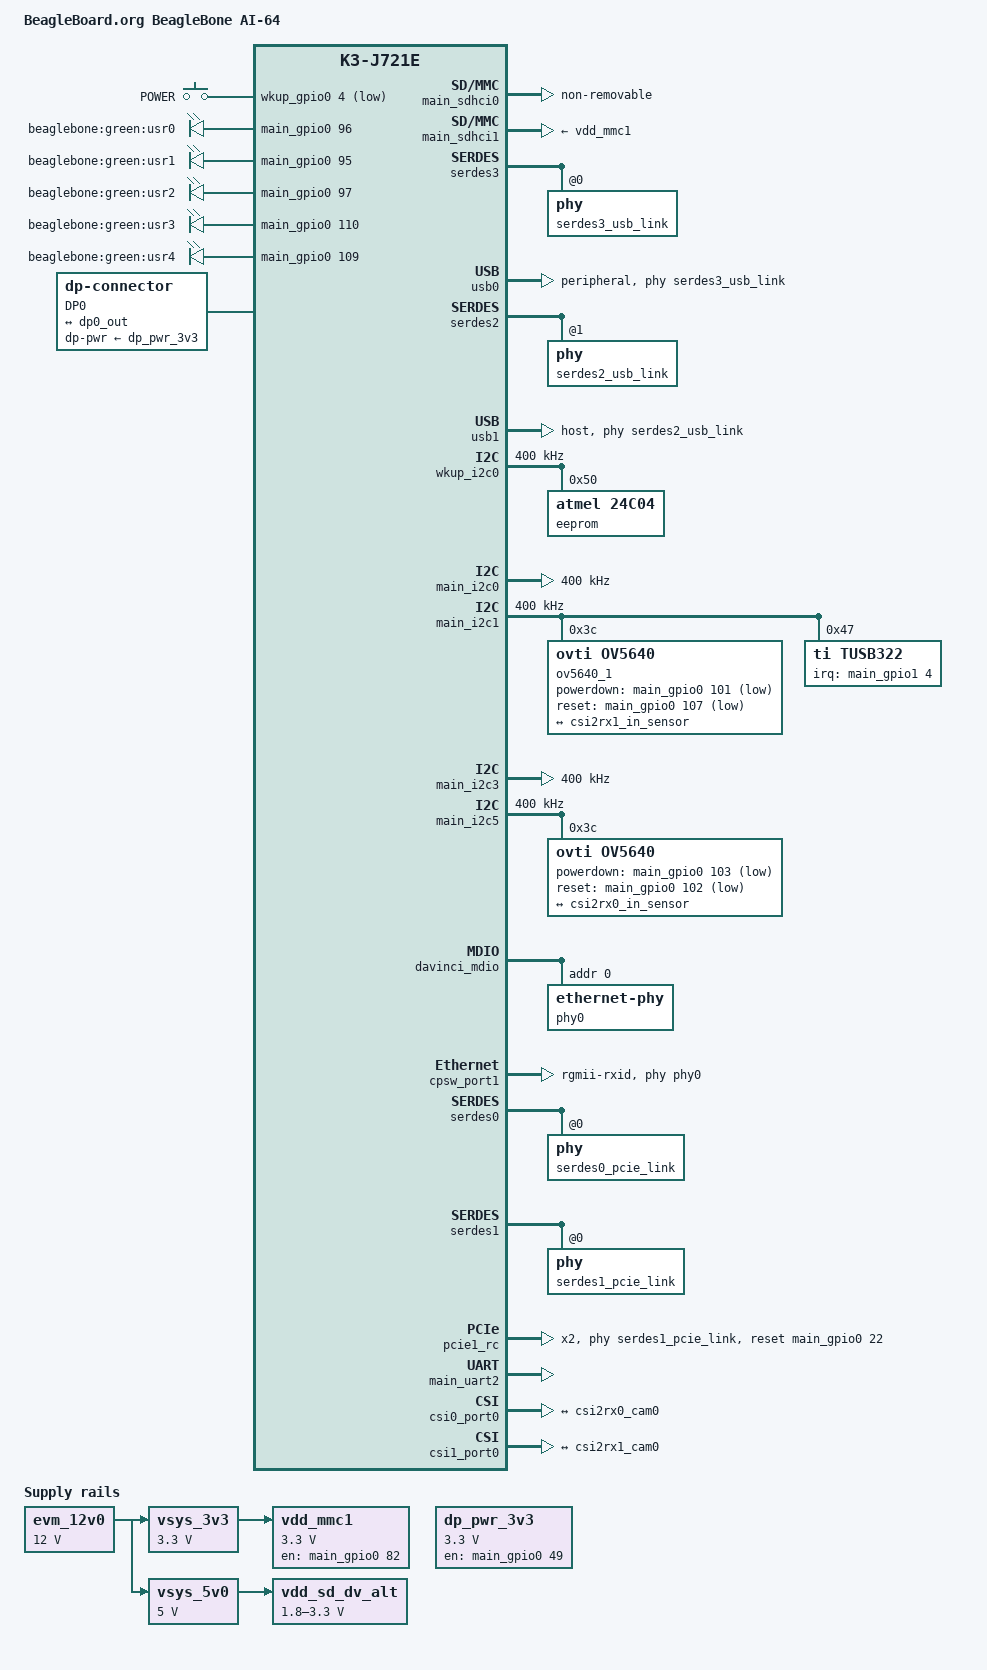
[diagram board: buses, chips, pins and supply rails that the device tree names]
// SPDX-License-Identifier: GPL-2.0
/*
 * Copyright (C) 2022 Texas Instruments Incorporated - https://www.ti.com/
 * Copyright (C) 2022 Jason Kridner, BeagleBoard.org Foundation
 */

/dts-v1/;

#include "k3-j721e-som-p0.dtsi"
//#include "k3-j721e-rtos-memory-map.dtsi"
#include <dt-bindings/gpio/gpio.h>
#include <dt-bindings/input/input.h>
#include <dt-bindings/net/ti-dp83867.h>
#include <dt-bindings/board/k3-j721e-bone-pins.h>

/ {

	model = "BeagleBoard.org BeagleBone AI-64";
	compatible = "beagle,j721e-beagleboneai64", "ti,j721e";

	chosen {
		stdout-path = "serial2:115200n8";
		bootargs = "console=ttyS2,115200n8 earlycon=ns16550a,mmio32,0x02800000";
		base_dtb = "k3-j721e-beagleboneai64.dts";
		base_dtb_timestamp = __TIMESTAMP__;
	};

	gpio_keys: gpio-keys {
		compatible = "gpio-keys";
		autorepeat;
		pinctrl-names = "default";
		pinctrl-0 = <&sw_pwr_pins_default>;

		sw_boot: sw1 {
			status = "disabled";
			label = "BOOT";
			linux,code = <BTN_0>;
			gpios = <&wkup_gpio0 0 GPIO_ACTIVE_LOW>;
		};

		sw_pwr: sw2 {
			label = "POWER";
			linux,code = <KEY_POWER>;
			gpios = <&wkup_gpio0 4 GPIO_ACTIVE_LOW>;
		};
	};

	gpio_leds: gpio-leds {
		compatible = "gpio-leds";
		pinctrl-names = "default";
		pinctrl-0 = <&led_pins_default>;

		usr_led0: usr_led0 {
			label = "beaglebone:green:usr0";
			default-state = "keep";
			linux,default-trigger = "heartbeat";
			gpios = <&main_gpio0 96 GPIO_ACTIVE_HIGH>;
		};

		usr_led1: usr_led1 {
			label = "beaglebone:green:usr1";
			default-state = "keep";
			linux,default-trigger = "mmc0";
			gpios = <&main_gpio0 95 GPIO_ACTIVE_HIGH>;
		};

		usr_led2: usr_led2 {
			label = "beaglebone:green:usr2";
			linux,default-trigger = "cpu";
			gpios = <&main_gpio0 97 GPIO_ACTIVE_HIGH>;
		};

		usr_led3: usr_led3 {
			label = "beaglebone:green:usr3";
			linux,default-trigger = "mmc1";
			gpios = <&main_gpio0 110 GPIO_ACTIVE_HIGH>;
		};

		usr_led4: usr_led4 {
			label = "beaglebone:green:usr4";
			linux,default-trigger = "netdev";
			gpios = <&main_gpio0 109 GPIO_ACTIVE_HIGH>;
		};

		bone_led_P8_03: led_P8_03 {
			status = "disabled";
			linux,default-trigger = "default-off";
			gpios = <gpio_P8_03 GPIO_ACTIVE_HIGH>;
		};

		bone_led_P8_04: led_P8_04 {
			status = "disabled";
			linux,default-trigger = "default-off";
			gpios = <gpio_P8_04 GPIO_ACTIVE_HIGH>;
		};

		bone_led_P8_05: led_P8_05 {
			status = "disabled";
			linux,default-trigger = "default-off";
			gpios = <gpio_P8_05 GPIO_ACTIVE_HIGH>;
		};

		bone_led_P8_06: led_P8_06 {
			status = "disabled";
			linux,default-trigger = "default-off";
			gpios = <gpio_P8_06 GPIO_ACTIVE_HIGH>;
		};

		bone_led_P8_07: led_P8_07 {
			status = "disabled";
			linux,default-trigger = "default-off";
			gpios = <gpio_P8_07 GPIO_ACTIVE_HIGH>;
		};

		bone_led_P8_08: led_P8_08 {
			status = "disabled";
			linux,default-trigger = "default-off";
			gpios = <gpio_P8_08 GPIO_ACTIVE_HIGH>;
		};

		bone_led_P8_09: led_P8_09 {
			status = "disabled";
			linux,default-trigger = "default-off";
			gpios = <gpio_P8_09 GPIO_ACTIVE_HIGH>;
		};

		bone_led_P8_10: led_P8_10 {
			status = "disabled";
			linux,default-trigger = "default-off";
			gpios = <gpio_P8_10 GPIO_ACTIVE_HIGH>;
		};

		bone_led_P8_11: led_P8_11 {
			status = "disabled";
			linux,default-trigger = "default-off";
			gpios = <gpio_P8_11 GPIO_ACTIVE_HIGH>;
		};

		bone_led_P8_12: led_P8_12 {
			status = "disabled";
			linux,default-trigger = "default-off";
			gpios = <gpio_P8_12 GPIO_ACTIVE_HIGH>;
		};

		bone_led_P8_13: led_P8_13 {
			status = "disabled";
			linux,default-trigger = "default-off";
			gpios = <gpio_P8_13 GPIO_ACTIVE_HIGH>;
		};

		bone_led_P8_14: led_P8_14 {
			status = "disabled";
			linux,default-trigger = "default-off";
			gpios = <gpio_P8_14 GPIO_ACTIVE_HIGH>;
		};

		bone_led_P8_15: led_P8_15 {
			status = "disabled";
			linux,default-trigger = "default-off";
			gpios = <gpio_P8_15 GPIO_ACTIVE_HIGH>;
		};

		bone_led_P8_16: led_P8_16 {
			status = "disabled";
			linux,default-trigger = "default-off";
			gpios = <gpio_P8_16 GPIO_ACTIVE_HIGH>;
		};

		bone_led_P8_17: led_P8_17 {
			status = "disabled";
			linux,default-trigger = "default-off";
			gpios = <gpio_P8_17 GPIO_ACTIVE_HIGH>;
		};

		bone_led_P8_18: led_P8_18 {
			status = "disabled";
			linux,default-trigger = "default-off";
			gpios = <gpio_P8_18 GPIO_ACTIVE_HIGH>;
		};

		bone_led_P8_19: led_P8_19 {
			status = "disabled";
			linux,default-trigger = "default-off";
			gpios = <gpio_P8_19 GPIO_ACTIVE_HIGH>;
		};

		bone_led_P8_20: led_P8_20 {
			status = "disabled";
			linux,default-trigger = "default-off";
			gpios = <gpio_P8_20 GPIO_ACTIVE_HIGH>;
		};

		bone_led_P8_21: led_P8_21 {
			status = "disabled";
			linux,default-trigger = "default-off";
			gpios = <gpio_P8_21 GPIO_ACTIVE_HIGH>;
		};

		bone_led_P8_22: led_P8_22 {
			status = "disabled";
			linux,default-trigger = "default-off";
			gpios = <gpio_P8_22 GPIO_ACTIVE_HIGH>;
		};

		bone_led_P8_23: led_P8_23 {
			status = "disabled";
			linux,default-trigger = "default-off";
			gpios = <gpio_P8_23 GPIO_ACTIVE_HIGH>;
		};

		bone_led_P8_24: led_P8_24 {
			status = "disabled";
			linux,default-trigger = "default-off";
			gpios = <gpio_P8_24 GPIO_ACTIVE_HIGH>;
		};

		bone_led_P8_25: led_P8_25 {
			status = "disabled";
			linux,default-trigger = "default-off";
			gpios = <gpio_P8_25 GPIO_ACTIVE_HIGH>;
		};

		bone_led_P8_26: led_P8_26 {
			status = "disabled";
			linux,default-trigger = "default-off";
			gpios = <gpio_P8_26 GPIO_ACTIVE_HIGH>;
		};

		bone_led_P8_27: led_P8_27 {
			status = "disabled";
			linux,default-trigger = "default-off";
			gpios = <gpio_P8_27 GPIO_ACTIVE_HIGH>;
		};

		bone_led_P8_28: led_P8_28 {
			status = "disabled";
			linux,default-trigger = "default-off";
			gpios = <gpio_P8_28 GPIO_ACTIVE_HIGH>;
		};

		bone_led_P8_29: led_P8_29 {
			status = "disabled";
			linux,default-trigger = "default-off";
			gpios = <gpio_P8_29 GPIO_ACTIVE_HIGH>;
		};

		bone_led_P8_30: led_P8_30 {
			status = "disabled";
			linux,default-trigger = "default-off";
			gpios = <gpio_P8_30 GPIO_ACTIVE_HIGH>;
		};

		bone_led_P8_31: led_P8_31 {
			status = "disabled";
			linux,default-trigger = "default-off";
			gpios = <gpio_P8_31 GPIO_ACTIVE_HIGH>;
		};

		bone_led_P8_32: led_P8_32 {
			status = "disabled";
			linux,default-trigger = "default-off";
			gpios = <gpio_P8_32 GPIO_ACTIVE_HIGH>;
		};

		bone_led_P8_33: led_P8_33 {
			status = "disabled";
			linux,default-trigger = "default-off";
			gpios = <gpio_P8_33 GPIO_ACTIVE_HIGH>;
		};

		bone_led_P8_34: led_P8_34 {
			status = "disabled";
			linux,default-trigger = "default-off";
			gpios = <gpio_P8_34 GPIO_ACTIVE_HIGH>;
		};

		bone_led_P8_35: led_P8_35 {
			status = "disabled";
			linux,default-trigger = "default-off";
			gpios = <gpio_P8_35 GPIO_ACTIVE_HIGH>;
		};

		bone_led_P8_36: led_P8_36 {
			status = "disabled";
			linux,default-trigger = "default-off";
			gpios = <gpio_P8_36 GPIO_ACTIVE_HIGH>;
		};

		bone_led_P8_37: led_P8_37 {
			status = "disabled";
			linux,default-trigger = "default-off";
			gpios = <gpio_P8_37 GPIO_ACTIVE_HIGH>;
		};

		bone_led_P8_38: led_P8_38 {
			status = "disabled";
			linux,default-trigger = "default-off";
			gpios = <gpio_P8_38 GPIO_ACTIVE_HIGH>;
		};

		bone_led_P8_39: led_P8_39 {
			status = "disabled";
			linux,default-trigger = "default-off";
			gpios = <gpio_P8_39 GPIO_ACTIVE_HIGH>;
		};

		bone_led_P8_40: led_P8_40 {
			status = "disabled";
			linux,default-trigger = "default-off";
			gpios = <gpio_P8_40 GPIO_ACTIVE_HIGH>;
		};

		bone_led_P8_41: led_P8_41 {
			status = "disabled";
			linux,default-trigger = "default-off";
			gpios = <gpio_P8_41 GPIO_ACTIVE_HIGH>;
		};

		bone_led_P8_42: led_P8_42 {
			status = "disabled";
			linux,default-trigger = "default-off";
			gpios = <gpio_P8_42 GPIO_ACTIVE_HIGH>;
		};

		bone_led_P8_43: led_P8_43 {
			status = "disabled";
			linux,default-trigger = "default-off";
			gpios = <gpio_P8_43 GPIO_ACTIVE_HIGH>;
		};

		bone_led_P8_44: led_P8_44 {
			status = "disabled";
			linux,default-trigger = "default-off";
			gpios = <gpio_P8_44 GPIO_ACTIVE_HIGH>;
		};

		bone_led_P8_45: led_P8_45 {
			status = "disabled";
			linux,default-trigger = "default-off";
			gpios = <gpio_P8_45 GPIO_ACTIVE_HIGH>;
		};

		bone_led_P8_46: led_P8_46 {
			status = "disabled";
			linux,default-trigger = "default-off";
			gpios = <gpio_P8_46 GPIO_ACTIVE_HIGH>;
		};

		bone_led_P9_11: led_P9_11 {
			status = "disabled";
			linux,default-trigger = "default-off";
			gpios = <gpio_P9_11 GPIO_ACTIVE_HIGH>;
		};

		bone_led_P9_12: led_P9_12 {
			status = "disabled";
			linux,default-trigger = "default-off";
			gpios = <gpio_P9_12 GPIO_ACTIVE_HIGH>;
		};

		bone_led_P9_13: led_P9_13 {
			status = "disabled";
			linux,default-trigger = "default-off";
			gpios = <gpio_P9_13 GPIO_ACTIVE_HIGH>;
		};

		bone_led_P9_14: led_P9_14 {
			status = "disabled";
			linux,default-trigger = "default-off";
			gpios = <gpio_P9_14 GPIO_ACTIVE_HIGH>;
		};

		bone_led_P9_15: led_P9_15 {
			status = "disabled";
			linux,default-trigger = "default-off";
			gpios = <gpio_P9_15 GPIO_ACTIVE_HIGH>;
		};

		bone_led_P9_16: led_P9_16 {
			status = "disabled";
			linux,default-trigger = "default-off";
			gpios = <gpio_P9_16 GPIO_ACTIVE_HIGH>;
		};

		bone_led_P9_17: led_P9_17 {
			status = "disabled";
			linux,default-trigger = "default-off";
			gpios = <gpio_P9_17 GPIO_ACTIVE_HIGH>;
		};

		bone_led_P9_18: led_P9_18 {
			status = "disabled";
			linux,default-trigger = "default-off";
			gpios = <gpio_P9_18 GPIO_ACTIVE_HIGH>;
		};

		bone_led_P9_19: led_P9_19 {
			status = "disabled";
			linux,default-trigger = "default-off";
			gpios = <gpio_P9_19 GPIO_ACTIVE_HIGH>;
		};

		bone_led_P9_20: led_P9_20 {
			status = "disabled";
			linux,default-trigger = "default-off";
			gpios = <gpio_P9_20 GPIO_ACTIVE_HIGH>;
		};

		bone_led_P9_21: led_P9_21 {
			status = "disabled";
			linux,default-trigger = "default-off";
			gpios = <gpio_P9_21 GPIO_ACTIVE_HIGH>;
		};

		bone_led_P9_22: led_P9_22 {
			status = "disabled";
			linux,default-trigger = "default-off";
			gpios = <gpio_P9_22 GPIO_ACTIVE_HIGH>;
		};

		bone_led_P9_23: led_P9_23 {
			status = "disabled";
			linux,default-trigger = "default-off";
			gpios = <gpio_P9_23 GPIO_ACTIVE_HIGH>;
		};

		bone_led_P9_24: led_P9_24 {
			status = "disabled";
			linux,default-trigger = "default-off";
			gpios = <gpio_P9_24 GPIO_ACTIVE_HIGH>;
		};

		bone_led_P9_25: led_P9_25 {
			status = "disabled";
			linux,default-trigger = "default-off";
			gpios = <gpio_P9_25 GPIO_ACTIVE_HIGH>;
		};

		bone_led_P9_26: led_P9_26 {
			status = "disabled";
			linux,default-trigger = "default-off";
			gpios = <gpio_P9_26 GPIO_ACTIVE_HIGH>;
		};

		bone_led_P9_27: led_P9_27 {
			status = "disabled";
			linux,default-trigger = "default-off";
			gpios = <gpio_P9_27 GPIO_ACTIVE_HIGH>;
		};

		bone_led_P9_28: led_P9_28 {
			status = "disabled";
			linux,default-trigger = "default-off";
			gpios = <gpio_P9_28 GPIO_ACTIVE_HIGH>;
		};

		bone_led_P9_29: led_P9_29 {
			status = "disabled";
			linux,default-trigger = "default-off";
			gpios = <gpio_P9_29 GPIO_ACTIVE_HIGH>;
		};

		bone_led_P9_30: led_P9_30 {
			status = "disabled";
			linux,default-trigger = "default-off";
			gpios = <gpio_P9_30 GPIO_ACTIVE_HIGH>;
		};

		bone_led_P9_31: led_P9_31 {
			status = "disabled";
			linux,default-trigger = "default-off";
			gpios = <gpio_P9_31 GPIO_ACTIVE_HIGH>;
		};

		bone_led_P9_33: led_P9_33 {
			status = "disabled";
			linux,default-trigger = "default-off";
			gpios = <gpio_P9_33 GPIO_ACTIVE_HIGH>;
		};

		bone_led_P9_35: led_P9_35 {
			status = "disabled";
			linux,default-trigger = "default-off";
			gpios = <gpio_P9_35 GPIO_ACTIVE_HIGH>;
		};

		bone_led_P9_36: led_P9_36 {
			status = "disabled";
			linux,default-trigger = "default-off";
			gpios = <gpio_P9_36 GPIO_ACTIVE_HIGH>;
		};

		bone_led_P9_37: led_P9_37 {
			status = "disabled";
			linux,default-trigger = "default-off";
			gpios = <gpio_P9_37 GPIO_ACTIVE_HIGH>;
		};

		bone_led_P9_38: led_P9_38 {
			status = "disabled";
			linux,default-trigger = "default-off";
			gpios = <gpio_P9_38 GPIO_ACTIVE_HIGH>;
		};

		bone_led_P9_39: led_P9_39 {
			status = "disabled";
			linux,default-trigger = "default-off";
			gpios = <gpio_P9_39 GPIO_ACTIVE_HIGH>;
		};

		bone_led_P9_40: led_P9_40 {
			status = "disabled";
			linux,default-trigger = "default-off";
			gpios = <gpio_P9_40 GPIO_ACTIVE_HIGH>;
		};

		bone_led_P9_41: led_P9_41 {
			status = "disabled";
			linux,default-trigger = "default-off";
			gpios = <gpio_P9_41 GPIO_ACTIVE_HIGH>;
		};

		bone_led_P9_42: led_P9_42 {
			status = "disabled";
			linux,default-trigger = "default-off";
			gpios = <gpio_P8_42 GPIO_ACTIVE_HIGH>;
		};
	};

	/* Dummy driver to request setup for cape header pins */
	cape_header: pinmux_dummy {
		compatible = "gpio-leds";
		pinctrl-names = "default";
		pinctrl-0 = <
			&P8_03_default_pin
			&P8_04_default_pin
			&P8_05_default_pin
			&P8_06_default_pin
			&P8_07_default_pin
			&P8_08_default_pin
			&P8_09_default_pin
			&P8_10_default_pin
			&P8_11_default_pin
			&P8_12_default_pin
			&P8_13_default_pin
			&P8_14_default_pin
			&P8_15_default_pin
			&P8_16_default_pin
			&P8_17_default_pin
			&P8_18_default_pin
			&P8_19_default_pin
			&P8_20_default_pin
			&P8_21_default_pin
			&P8_22_default_pin
			&P8_23_default_pin
			&P8_24_default_pin
			&P8_25_default_pin
			&P8_26_default_pin
			&P8_27_default_pin
			&P8_28_default_pin
			&P8_29_default_pin
			&P8_30_default_pin
			&P8_31_default_pin
			&P8_32_default_pin
			&P8_33_default_pin
			&P8_34_default_pin
			&P8_35_default_pin
			&P8_36_default_pin
			&P8_37_default_pin
			&P8_38_default_pin
			&P8_39_default_pin
			&P8_40_default_pin
			&P8_41_default_pin
			&P8_42_default_pin
			&P8_43_default_pin
			&P8_44_default_pin
			&P8_45_default_pin
			&P8_46_default_pin
			&P9_11_default_pin
			&P9_12_default_pin
			&P9_13_default_pin
			&P9_14_default_pin
			&P9_15_default_pin
			&P9_16_default_pin
			&P9_17_default_pin
			&P9_18_default_pin
			&P9_19_default_pin
			&P9_20_default_pin
			&P9_21_default_pin
			&P9_22_default_pin
			&P9_23_default_pin
			&P9_24_default_pin
			&P9_25_default_pin
			&P9_26_default_pin
			&P9_27_default_pin
			&P9_28_default_pin
			&P9_29_default_pin
			&P9_30_default_pin
			&P9_31_default_pin
			&P9_33_default_pin
			&P9_35_default_pin
			&P9_36_default_pin
			&P9_37_default_pin
			&P9_38_default_pin
			&P9_39_default_pin
			&P9_40_default_pin
			&P9_41_default_pin
			&P9_42_default_pin
		>;
	};

	evm_12v0: fixedregulator-evm12v0 {
		/* main supply */
		compatible = "regulator-fixed";
		regulator-name = "evm_12v0";
		regulator-min-microvolt = <12000000>;
		regulator-max-microvolt = <12000000>;
		regulator-always-on;
		regulator-boot-on;
	};

	vsys_3v3: fixedregulator-vsys3v3 {
		/* Output of LMS140 */
		compatible = "regulator-fixed";
		regulator-name = "vsys_3v3";
		regulator-min-microvolt = <3300000>;
		regulator-max-microvolt = <3300000>;
		vin-supply = <&evm_12v0>;
		regulator-always-on;
		regulator-boot-on;
	};

	vsys_5v0: fixedregulator-vsys5v0 {
		/* Output of LM5140 */
		compatible = "regulator-fixed";
		regulator-name = "vsys_5v0";
		regulator-min-microvolt = <5000000>;
		regulator-max-microvolt = <5000000>;
		vin-supply = <&evm_12v0>;
		regulator-always-on;
		regulator-boot-on;
	};

	vdd_mmc1: fixedregulator-sd {
		compatible = "regulator-fixed";
		pinctrl-names = "default";
		pinctrl-0 = <&sd_pwr_en_pins_default>;
		regulator-name = "vdd_mmc1";
		regulator-min-microvolt = <3300000>;
		regulator-max-microvolt = <3300000>;
		regulator-boot-on;
		enable-active-high;
		vin-supply = <&vsys_3v3>;
		gpios = <&main_gpio0 82 GPIO_ACTIVE_HIGH>;
	};

	vdd_sd_dv_alt: gpio-regulator-TLV71033 {
		compatible = "regulator-gpio";
		pinctrl-names = "default";
		pinctrl-0 = <&vdd_sd_dv_alt_pins_default>;
		regulator-name = "tlv71033";
		regulator-min-microvolt = <1800000>;
		regulator-max-microvolt = <3300000>;
		regulator-boot-on;
		vin-supply = <&vsys_5v0>;
		gpios = <&main_gpio0 117 GPIO_ACTIVE_HIGH>;
		states = <1800000 0x0>,
			 <3300000 0x1>;
	};

	cpsw9g_virt_mac: main_r5fss_cpsw9g_virt_mac0 {
		compatible = "ti,j721e-cpsw-virt-mac";
		dma-coherent;
		ti,psil-base = <0x4a00>;
		ti,remote-name = "mpu_1_0_ethswitch-device-0";

		dmas = <&main_udmap 0xca00>,
		       <&main_udmap 0xca01>,
		       <&main_udmap 0xca02>,
		       <&main_udmap 0xca03>,
		       <&main_udmap 0xca04>,
		       <&main_udmap 0xca05>,
		       <&main_udmap 0xca06>,
		       <&main_udmap 0xca07>,
		       <&main_udmap 0x4a00>;
		dma-names = "tx0", "tx1", "tx2", "tx3",
			    "tx4", "tx5", "tx6", "tx7",
			    "rx";

		virt_emac_port {
			ti,label = "virt-port";
			/* local-mac-address = [0 0 0 0 0 0]; */
		};
	};

	transceiver1: can-phy@0 {
		status = "disabled";
	};

	transceiver2: can-phy@1 {
		status = "disabled";
	};

	dp_pwr_3v3: fixedregulator-dp-prw {
		compatible = "regulator-fixed";
		pinctrl-names = "default";
		pinctrl-0 = <&dp0_3v3_en_pins_default>;
		regulator-name = "dp-pwr";
		regulator-min-microvolt = <3300000>;
		regulator-max-microvolt = <3300000>;
		gpios = <&main_gpio0 49 GPIO_ACTIVE_HIGH>; /* DP0_PWR_SW_EN */
		enable-active-high;

		/* Always on for now, until dp-connector driver can handle this */
		regulator-always-on;
	};

	dp0: connector {
		compatible = "dp-connector";
		label = "DP0";
		type = "full-size";
		dp-pwr-supply = <&dp_pwr_3v3>;

		port {
			dp_connector_in: endpoint {
				remote-endpoint = <&dp0_out>;
			};
		};
	};

	clk_ov5640_fixed: ov5640-xclk {
		compatible = "fixed-clock";
		#clock-cells = <0>;
		clock-frequency = <25000000>;
	};
};

&main_pmx0 {
	led_pins_default: led-pins-default {
		pinctrl-single,pins = <
			J721E_IOPAD(0x184, PIN_INPUT, 7) /* (T23) RGMII5_RD0.GPIO0_96 */
			J721E_IOPAD(0x180, PIN_INPUT, 7) /* (R23) RGMII5_RD1.GPIO0_95 */
			J721E_IOPAD(0x188, PIN_INPUT, 7) /* (Y28) RGMII6_TX_CTL.GPIO0_97 */
			J721E_IOPAD(0x1bc, PIN_INPUT, 7) /* (V24) MDIO0_MDC.GPIO0_110 */
			J721E_IOPAD(0x1b8, PIN_INPUT, 7) /* (V26) MDIO0_MDIO.GPIO0_109 */
		>;
	};

	main_mmc1_pins_default: main-mmc1-pins-default {
		pinctrl-single,pins = <
			J721E_IOPAD(0x254, PIN_INPUT, 0) /* (R29) MMC1_CMD */
			J721E_IOPAD(0x250, PIN_INPUT, 0) /* (P25) MMC1_CLK */
			J721E_IOPAD(0x2ac, PIN_INPUT, 0) /* (P25) MMC1_CLKLB */
			J721E_IOPAD(0x24c, PIN_INPUT, 0) /* (R24) MMC1_DAT0 */
			J721E_IOPAD(0x248, PIN_INPUT, 0) /* (P24) MMC1_DAT1 */
			J721E_IOPAD(0x244, PIN_INPUT, 0) /* (R25) MMC1_DAT2 */
			J721E_IOPAD(0x240, PIN_INPUT, 0) /* (R26) MMC1_DAT3 */
			J721E_IOPAD(0x258, PIN_INPUT, 0) /* (P23) MMC1_SDCD */
		>;
	};

	sd_pwr_en_pins_default: sd-pwr-en-pins-default {
		pinctrl-single,pins = <
			J721E_IOPAD(0x14c, PIN_INPUT, 7) /* (AA29) PRG0_PRU1_GPO19.GPIO0_82 */
		>;
	};

	vdd_sd_dv_alt_pins_default: vdd-sd-dv-alt-pins-default {
		pinctrl-single,pins = <
			J721E_IOPAD(0x1d8, PIN_INPUT, 7) /* (W4) SPI1_CS1.GPIO0_117 */
		>;
	};

	main_usbss0_pins_default: main-usbss0-pins-default {
		pinctrl-single,pins = <
			J721E_IOPAD(0x210, PIN_INPUT, 7) /* (W3) MCAN1_RX.GPIO1_3 - USBC_DIR */
		>;
	};

	tusb322_pins_default: tusb322-pins-default {
		pinctrl-single,pins = <
			J721E_IOPAD(0x214, PIN_INPUT, 7) /* (V4) MCAN1_TX.GPIO1_4 -- USBC_INT */
		>;
	};

	main_usbss1_pins_default: main-usbss1-pins-default {
		pinctrl-single,pins = <
			J721E_IOPAD(0x290, INPUT_DISABLE, 1) /* (U6) USB0_DRVVBUS.USB1_DRVVBUS */
		>;
	};

	dp0_3v3_en_pins_default:dp0-3v3-en-pins-default {
		pinctrl-single,pins = <
			J721E_IOPAD(0xc8, PIN_INPUT, 7) /* (AE26) PRG0_PRU0_GPO6.GPIO0_49 */
		>;
	};

	dp0_pins_default: dp0-pins-default {
		pinctrl-single,pins = <
			J721E_IOPAD(0x1c4, PIN_INPUT, 5) /* (Y4) SPI0_CS1.DP0_HPD */
		>;
	};

	main_i2c0_pins_default: main-i2c0-pins-default {
		pinctrl-single,pins = <
			J721E_IOPAD(0x220, PIN_INPUT_PULLUP, 0) /* (AC5) I2C0_SCL */
			J721E_IOPAD(0x224, PIN_INPUT_PULLUP, 0) /* (AA5) I2C0_SDA */
		>;
	};

	main_i2c1_pins_default: main-i2c1-pins-default {
		pinctrl-single,pins = <
			J721E_IOPAD(0x228, PIN_INPUT_PULLUP, 0) /* (Y6) I2C1_SCL */
			J721E_IOPAD(0x22c, PIN_INPUT_PULLUP, 0) /* (AA6) I2C1_SDA */
		>;
	};

	main_i2c3_pins_default: main-i2c3-pins-default {
		pinctrl-single,pins = <
			J721E_IOPAD(0x270, PIN_INPUT_PULLUP, 4) /* (T26) MMC2_CLK.I2C3_SCL */
			J721E_IOPAD(0x274, PIN_INPUT_PULLUP, 4) /* (T25) MMC2_CMD.I2C3_SDA */
		>;
	};

	main_i2c5_pins_default: main-i2c5-pins-default {
		pinctrl-single,pins = <
			J721E_IOPAD(0x150, PIN_INPUT_PULLUP, 2) /* (Y26) PRG0_MDIO0_MDIO.I2C5_SCL */
			J721E_IOPAD(0x154, PIN_INPUT_PULLUP, 2) /* (AA27) PRG0_MDIO0_MDC.I2C5_SDA */
		>;
	};

	main_spi6_pins_default: main-spi6-pins-default {
		pinctrl-single,pins = <
			J721E_IOPAD(0x74, INPUT_DISABLE, 4) /* (AC21) PRG1_PRU1_GPO7.SPI6_CS0 */
			J721E_IOPAD(0x28, INPUT_DISABLE, 4) /* (AG20) PRG1_PRU0_GPO9.SPI6_CS1 */
			J721E_IOPAD(0x9c, INPUT_DISABLE, 4) /* (AC22) PRG1_PRU1_GPO17.SPI6_CLK */
			J721E_IOPAD(0xa0, INPUT_DISABLE, 4) /* (AJ22) PRG1_PRU1_GPO18.SPI6_D0 */
			J721E_IOPAD(0xa4, PIN_INPUT, 4) /* (AH22) PRG1_PRU1_GPO19.SPI6_D1 */
		>;
	};

	csi0_gpio_pins_default: csi0-gpio-pins-default {
		pinctrl-single,pins = <
			J721E_IOPAD(0x19c, PIN_INPUT_PULLDOWN, 7) /* (W27) RGMII6_TD0.GPIO0_102 */
			J721E_IOPAD(0x1a0, PIN_INPUT_PULLDOWN, 7) /* (W29) RGMII6_TXC.GPIO0_103 */
		>;
	};

	csi1_gpio_pins_default: csi1-gpio-pins-default {
		pinctrl-single,pins = <
			J721E_IOPAD(0x198, PIN_INPUT_PULLDOWN, 7) /* (V25) RGMII6_TD1.GPIO0_101 */
			J721E_IOPAD(0x1b0, PIN_INPUT_PULLDOWN, 7) /* (W24) RGMII6_RD1.GPIO0_107 */
		>;
	};

/* macro: BONE_PIN( <pin>, <mode_name>, <register_value_macro(s)> */
#define BONE_PIN(XX,ZZ,QQ) \
	XX##_##ZZ##_pin: pinmux_##XX##_##ZZ##_pin { pinctrl-single,pins = < QQ >; };

	/* I2C : https://elinux.org/Beagleboard:BeagleBone_cape_interface_spec#I2C */
	/* i2c6 P9.17 P9.18 */
	/* i2c2 P9.19 P9.20 */
	/* i2c4 P9.24 P9.26 */

	/* CAN : https://elinux.org/Beagleboard:BeagleBone_cape_interface_spec#CAN */
	/* mcan0 P9.20 P9.19 */
	/* mcan4 P9.26 P9.24 */
	/* mcan5 P8.08 P8.07 */

	/* SPI : https://elinux.org/Beagleboard:BeagleBone_cape_interface_spec#SPI */
	/* spi6 P9.18 P9.21 P9.22 P9.16 P9.23 */
	/* spi7 P9.30 P9.29 P9.31 P9.29 P9.42 */

	/* UART : https://elinux.org/Beagleboard:BeagleBone_cape_interface_spec#UART */
	/* uart0 P9.13 P9.11 */
	/* uart2 P9.24 P9.22 */
	/* uart5 P8.37 P8.38 P8.32 P8.31 */

	/* PWM: https://elinux.org/Beagleboard:BeagleBone_cape_interface_spec#PWM */
	/* ehrpwm1 P9.22 P9.21 */
	/* ehrpwm2 P9.14 P9.16 */
	/* ehrpwm0 P8.19 P8.13 */

	/* Full P8/P9 header mode definitions */
	/* P8_01 - GND */
	/* P8_02 - GND */

	/* P8_03 (AH21) PRG1_PRU0_GPO19 (gpio0_20) AH21_MCAN6_TX */
	BONE_PIN(P8_03, default,   P8_03(PIN_INPUT, 7))
	BONE_PIN(P8_03, pruout,    P8_03(PIN_OUTPUT, 0))	/* prg1_pru0_gpo19 */
	BONE_PIN(P8_03, pruin,     P8_03(PIN_INPUT, 1))		/* prg1_pru0_gpi19 */
	BONE_PIN(P8_03, gpio,      P8_03(PIN_INPUT, 7))
	BONE_PIN(P8_03, gpio_pu,   P8_03(PIN_INPUT_PULLUP, 7))
	BONE_PIN(P8_03, gpio_pd,   P8_03(PIN_INPUT_PULLDOWN, 7))

	/* P8_04 (AC29) PRG0_PRU0_GPO5 (gpio0_48) AC29_SYS_BOOTMODE2 */
	BONE_PIN(P8_04, default,   P8_04(PIN_INPUT, 7))
	BONE_PIN(P8_04, pruout,    P8_04(PIN_OUTPUT, 0))	/* prg0_pru0_gpo5 */
	BONE_PIN(P8_04, pruin,     P8_04(PIN_INPUT, 1))		/* prg0_pru0_gpi5 */
	BONE_PIN(P8_04, gpio,      P8_04(PIN_INPUT, 7))
	BONE_PIN(P8_04, gpio_pu,   P8_04(PIN_INPUT_PULLUP, 7))
	BONE_PIN(P8_04, gpio_pd,   P8_04(PIN_INPUT_PULLDOWN, 7))

	/* P8_05 (AH25) PRG1_PRU1_GPO12 (gpio0_33) AH25_MCAN7_TX */
	BONE_PIN(P8_05, default,   P8_05(PIN_INPUT, 7))
	BONE_PIN(P8_05, pruout,    P8_05(PIN_OUTPUT, 0))	/* prg1_pru1_gpo12 */
	BONE_PIN(P8_05, pruin,     P8_05(PIN_INPUT, 1))		/* prg1_pru1_gpi12 */
	BONE_PIN(P8_05, gpio,      P8_05(PIN_INPUT, 7))
	BONE_PIN(P8_05, gpio_pu,   P8_05(PIN_INPUT_PULLUP, 7))
	BONE_PIN(P8_05, gpio_pd,   P8_05(PIN_INPUT_PULLDOWN, 7))

	/* P8_06 (AG25) PRG1_PRU1_GPO13 (gpio0_34) AG25_MCAN7_RX */
	BONE_PIN(P8_06, default,   P8_06(PIN_INPUT, 7))
	BONE_PIN(P8_06, pruout,    P8_06(PIN_OUTPUT, 0))	/* prg1_pru1_gpo13 */
	BONE_PIN(P8_06, pruin,     P8_06(PIN_INPUT, 1))		/* prg1_pru1_gpi13 */
	BONE_PIN(P8_06, gpio,      P8_06(PIN_INPUT, 7))
	BONE_PIN(P8_06, gpio_pu,   P8_06(PIN_INPUT_PULLUP, 7))
	BONE_PIN(P8_06, gpio_pd,   P8_06(PIN_INPUT_PULLDOWN, 7))

	/* P8_07 (AD24) PRG1_PRU0_GPO14 (gpio0_15) AD24_MCAN5_RX */
	BONE_PIN(P8_07, default,   P8_07(PIN_INPUT, 7))
	BONE_PIN(P8_07, pruout,    P8_07(PIN_OUTPUT, 0))	/* prg1_pru0_gpo14 */
	BONE_PIN(P8_07, pruin,     P8_07(PIN_INPUT, 1))		/* prg1_pru0_gpi14 */
	BONE_PIN(P8_07, can,       P8_07(PIN_INPUT, 6))	/* mcan5_rx */
	BONE_PIN(P8_07, gpio,      P8_07(PIN_INPUT, 7))
	BONE_PIN(P8_07, gpio_pu,   P8_07(PIN_INPUT_PULLUP, 7))
	BONE_PIN(P8_07, gpio_pd,   P8_07(PIN_INPUT_PULLDOWN, 7))

	/* P8_08 (AG24) PRG1_PRU0_GPO13 (gpio0_14) AG24_MCAN5_TX */
	BONE_PIN(P8_08, default,   P8_08(PIN_INPUT, 7))
	BONE_PIN(P8_08, pruout,    P8_08(PIN_OUTPUT, 0))	/* prg1_pru0_gpo13 */
	BONE_PIN(P8_08, pruin,     P8_08(PIN_INPUT, 1))		/* prg1_pru0_gpi13 */
	BONE_PIN(P8_08, can,       P8_08(PIN_OUTPUT, 6))	/* mcan5_tx */
	BONE_PIN(P8_08, gpio,      P8_08(PIN_INPUT, 7))
	BONE_PIN(P8_08, gpio_pu,   P8_08(PIN_INPUT_PULLUP, 7))
	BONE_PIN(P8_08, gpio_pd,   P8_08(PIN_INPUT_PULLDOWN, 7))

	/* P8_09 (AE24) PRG1_PRU0_GPO16 (gpio0_17) AE24_MCAN6_RX */
	BONE_PIN(P8_09, default,   P8_09(PIN_INPUT, 7))
	BONE_PIN(P8_09, pruout,    P8_09(PIN_OUTPUT, 0))	/* prg1_pru0_gpo16 */
	BONE_PIN(P8_09, pruin,     P8_09(PIN_INPUT, 1))		/* prg1_pru0_gpi16 */
	BONE_PIN(P8_09, gpio,      P8_09(PIN_INPUT, 7))
	BONE_PIN(P8_09, gpio_pu,   P8_09(PIN_INPUT_PULLUP, 7))
	BONE_PIN(P8_09, gpio_pd,   P8_09(PIN_INPUT_PULLDOWN, 7))

	/* P8_10 (AC24) PRG1_PRU0_GPO15 (gpio0_16) AC24_MCAN6_TX */
	BONE_PIN(P8_10, default,   P8_10(PIN_INPUT, 7))
	BONE_PIN(P8_10, pruout,    P8_10(PIN_OUTPUT, 0))	/* prg1_pru0_gpo15 */
	BONE_PIN(P8_10, pruin,     P8_10(PIN_INPUT, 1))		/* prg1_pru0_gpi15 */
	BONE_PIN(P8_10, gpio,      P8_10(PIN_INPUT, 7))
	BONE_PIN(P8_10, gpio_pu,   P8_10(PIN_INPUT_PULLUP, 7))
	BONE_PIN(P8_10, gpio_pd,   P8_10(PIN_INPUT_PULLDOWN, 7))

	/* P8_11 (AB24) PRG0_PRU0_GPO17 (gpio0_60) AB24_SYS_BOOTMODE7 */
	BONE_PIN(P8_11, default,   P8_11(PIN_INPUT, 7))
	BONE_PIN(P8_11, pruout,    P8_11(PIN_OUTPUT, 0))	/* prg0_pru0_gpo17 */
	BONE_PIN(P8_11, pruin,     P8_11(PIN_INPUT, 1))		/* prg0_pru0_gpi17 */
	BONE_PIN(P8_11, gpio,      P8_11(PIN_INPUT, 7))
	BONE_PIN(P8_11, gpio_pu,   P8_11(PIN_INPUT_PULLUP, 7))
	BONE_PIN(P8_11, gpio_pd,   P8_11(PIN_INPUT_PULLDOWN, 7))

	/* P8_12 (AH28) PRG0_PRU0_GPO16 (gpio0_59) AH28_PRG0_PWM0_A2 */
	BONE_PIN(P8_12, default,   P8_12(PIN_INPUT, 7))
	BONE_PIN(P8_12, pruout,    P8_12(PIN_OUTPUT, 0))	/* prg0_pru0_gpo16 */
	BONE_PIN(P8_12, pruin,     P8_12(PIN_INPUT, 1))		/* prg0_pru0_gpi16 */
	BONE_PIN(P8_12, gpio,      P8_12(PIN_INPUT, 7))
	BONE_PIN(P8_12, gpio_pu,   P8_12(PIN_INPUT_PULLUP, 7))
	BONE_PIN(P8_12, gpio_pd,   P8_12(PIN_INPUT_PULLDOWN, 7))

	/* P8_13 (V27) RGMII5_TD1 (gpio0_89) V27_EHRPWM0_B */
	BONE_PIN(P8_13, default,   P8_13(PIN_INPUT, 7))
	BONE_PIN(P8_13, gpio,      P8_13(PIN_INPUT, 7))
	BONE_PIN(P8_13, gpio_pu,   P8_13(PIN_INPUT_PULLUP, 7))
	BONE_PIN(P8_13, gpio_pd,   P8_13(PIN_INPUT_PULLDOWN, 7))
	BONE_PIN(P8_13, pwm,       P8_13(PIN_OUTPUT, 6))	/* ehrpwm0_b */

	/* P8_14 (AF27) PRG0_PRU1_GPO12 (gpio0_75) AF27_PRG0_PWM1_A0 */
	BONE_PIN(P8_14, default,   P8_14(PIN_INPUT, 7))
	BONE_PIN(P8_14, pruout,    P8_14(PIN_OUTPUT, 0))	/* prg0_pru1_gpo12 */
	BONE_PIN(P8_14, pruin,     P8_14(PIN_INPUT, 1))		/* prg0_pru1_gpi12 */
	BONE_PIN(P8_14, gpio,      P8_14(PIN_INPUT, 7))
	BONE_PIN(P8_14, gpio_pu,   P8_14(PIN_INPUT_PULLUP, 7))
	BONE_PIN(P8_14, gpio_pd,   P8_14(PIN_INPUT_PULLDOWN, 7))

	/* P8_15 (AB29) PRG0_PRU0_GPO18 (gpio0_61) AB29_PRG0_ECAP0_IN_APWM_OUT */
	BONE_PIN(P8_15, default,   P8_15(PIN_INPUT, 7))
	BONE_PIN(P8_15, pruout,    P8_15(PIN_OUTPUT, 0))	/* prg0_pru0_gpo18 */
	BONE_PIN(P8_15, pruin,     P8_15(PIN_INPUT, 1))		/* prg0_pru0_gpi18 */
	BONE_PIN(P8_15, gpio,      P8_15(PIN_INPUT, 7))
	BONE_PIN(P8_15, gpio_pu,   P8_15(PIN_INPUT_PULLUP, 7))
	BONE_PIN(P8_15, gpio_pd,   P8_15(PIN_INPUT_PULLDOWN, 7))

	/* P8_16 (AB28) PRG0_PRU0_GPO19 (gpio0_62) AB28_PRG0_PWM0_TZ_OUT */
	BONE_PIN(P8_16, default,   P8_16(PIN_INPUT, 7))
	BONE_PIN(P8_16, pruout,    P8_16(PIN_OUTPUT, 0))	/* prg0_pru0_gpo19 */
	BONE_PIN(P8_16, pruin,     P8_16(PIN_INPUT, 1))		/* prg0_pru0_gpi19 */
	BONE_PIN(P8_16, gpio,      P8_16(PIN_INPUT, 7))
	BONE_PIN(P8_16, gpio_pu,   P8_16(PIN_INPUT_PULLUP, 7))
	BONE_PIN(P8_16, gpio_pd,   P8_16(PIN_INPUT_PULLDOWN, 7))

	/* P8_17 (AF22) PRG1_PRU0_GPO2 (gpio0_3) AF22_PRG1_PWM2_A0 */
	BONE_PIN(P8_17, default,   P8_17(PIN_INPUT, 7))
	BONE_PIN(P8_17, pruout,    P8_17(PIN_OUTPUT, 0))	/* prg1_pru0_gpo2 */
	BONE_PIN(P8_17, pruin,     P8_17(PIN_INPUT, 1))		/* prg1_pru0_gpi2 */
	BONE_PIN(P8_17, gpio,      P8_17(PIN_INPUT, 7))
	BONE_PIN(P8_17, gpio_pu,   P8_17(PIN_INPUT_PULLUP, 7))
	BONE_PIN(P8_17, gpio_pd,   P8_17(PIN_INPUT_PULLDOWN, 7))

	/* P8_18 (AJ23) PRG1_PRU0_GPO3 (gpio0_4) AJ23_PRG1_PWM3_A2 */
	BONE_PIN(P8_18, default,   P8_18(PIN_INPUT, 7))
	BONE_PIN(P8_18, pruout,    P8_18(PIN_OUTPUT, 0))	/* prg1_pru0_gpo3 */
	BONE_PIN(P8_18, pruin,     P8_18(PIN_INPUT, 1))		/* prg1_pru0_gpi3 */
	BONE_PIN(P8_18, gpio,      P8_18(PIN_INPUT, 7))
	BONE_PIN(P8_18, gpio_pu,   P8_18(PIN_INPUT_PULLUP, 7))
	BONE_PIN(P8_18, gpio_pd,   P8_18(PIN_INPUT_PULLDOWN, 7))

	/* P8_19 (V29) RGMII5_TD2 (gpio0_88) V29_EHRPWM0_A */
	BONE_PIN(P8_19, default,   P8_19(PIN_INPUT, 7))
	BONE_PIN(P8_19, gpio,      P8_19(PIN_INPUT, 7))
	BONE_PIN(P8_19, gpio_pu,   P8_19(PIN_INPUT_PULLUP, 7))
	BONE_PIN(P8_19, gpio_pd,   P8_19(PIN_INPUT_PULLDOWN, 7))
	BONE_PIN(P8_19, pwm,       P8_19(PIN_OUTPUT, 6))	/* ehrpwm0_a */

	/* P8_20 (AF26) PRG0_PRU1_GPO13 (gpio0_76) AF26_PRG0_PWM1_B0 */
	BONE_PIN(P8_20, default,   P8_20(PIN_INPUT, 7))
	BONE_PIN(P8_20, pruout,    P8_20(PIN_OUTPUT, 0))	/* prg0_pru1_gpo13 */
	BONE_PIN(P8_20, pruin,     P8_20(PIN_INPUT, 1))		/* prg0_pru1_gpi13 */
	BONE_PIN(P8_20, gpio,      P8_20(PIN_INPUT, 7))
	BONE_PIN(P8_20, gpio_pu,   P8_20(PIN_INPUT_PULLUP, 7))
	BONE_PIN(P8_20, gpio_pd,   P8_20(PIN_INPUT_PULLDOWN, 7))

	/* P8_21 (AF21) PRG1_PRU1_GPO9 (gpio0_30) AF21_MCAN8_TX */
	BONE_PIN(P8_21, default,   P8_21(PIN_INPUT, 7))
	BONE_PIN(P8_21, pruout,    P8_21(PIN_OUTPUT, 0))	/* prg1_pru1_gpo9 */
	BONE_PIN(P8_21, pruin,     P8_21(PIN_INPUT, 1))		/* prg1_pru1_gpi9 */
	BONE_PIN(P8_21, gpio,      P8_21(PIN_INPUT, 7))
	BONE_PIN(P8_21, gpio_pu,   P8_21(PIN_INPUT_PULLUP, 7))
	BONE_PIN(P8_21, gpio_pd,   P8_21(PIN_INPUT_PULLDOWN, 7))
	BONE_PIN(P8_21, spi,       P8_21(PIN_OUTPUT, 4))	/* spi6_cs3 */

	/* P8_22 (AH23) PRG1_PRU0_GPO4 (gpio0_5) AH23_UART2_RXD */
	BONE_PIN(P8_22, default,   P8_22(PIN_INPUT, 7))
	BONE_PIN(P8_22, pruout,    P8_22(PIN_OUTPUT, 0))	/* prg1_pru0_gpo4 */
	BONE_PIN(P8_22, pruin,     P8_22(PIN_INPUT, 1))		/* prg1_pru0_gpi4 */
	BONE_PIN(P8_22, gpio,      P8_22(PIN_INPUT, 7))
	BONE_PIN(P8_22, gpio_pu,   P8_22(PIN_INPUT_PULLUP, 7))
	BONE_PIN(P8_22, gpio_pd,   P8_22(PIN_INPUT_PULLDOWN, 7))
	BONE_PIN(P8_22, uart,      P8_22(PIN_INPUT, 14))	/* uart2_rxd */

	/* P8_23 (AB23) PRG1_PRU1_GPO10 (gpio0_31) AB23_MCAN8_RX */
	BONE_PIN(P8_23, default,   P8_23(PIN_INPUT, 7))
	BONE_PIN(P8_23, pruout,    P8_23(PIN_OUTPUT, 0))	/* prg1_pru1_gpo10 */
	BONE_PIN(P8_23, pruin,     P8_23(PIN_INPUT, 1))		/* prg1_pru1_gpi10 */
	BONE_PIN(P8_23, pruuart,   P8_23(PIN_OUTPUT, 2))
	BONE_PIN(P8_23, gpio,      P8_23(PIN_INPUT, 7))
	BONE_PIN(P8_23, gpio_pu,   P8_23(PIN_INPUT_PULLUP, 7))
	BONE_PIN(P8_23, gpio_pd,   P8_23(PIN_INPUT_PULLDOWN, 7))

	/* P8_24 (AD20) PRG1_PRU0_GPO5 (gpio0_6) AD20_SYS_BOOTMODE0 */
	BONE_PIN(P8_24, default,   P8_24(PIN_INPUT, 7))
	BONE_PIN(P8_24, pruout,    P8_24(PIN_OUTPUT, 0))	/* prg1_pru0_gpo5 */
	BONE_PIN(P8_24, pruin,     P8_24(PIN_INPUT, 1))		/* prg1_pru0_gpi5 */
	BONE_PIN(P8_24, gpio,      P8_24(PIN_INPUT, 7))
	BONE_PIN(P8_24, gpio_pu,   P8_24(PIN_INPUT_PULLUP, 7))
	BONE_PIN(P8_24, gpio_pd,   P8_24(PIN_INPUT_PULLDOWN, 7))

	/* P8_25 (AH26) PRG1_PRU1_GPO14 (gpio0_35) AH26_PRG1_PRU1_GPO14 */
	BONE_PIN(P8_25, default,   P8_25(PIN_INPUT, 7))
	BONE_PIN(P8_25, pruout,    P8_25(PIN_OUTPUT, 0))	/* prg1_pru1_gpo14 */
	BONE_PIN(P8_25, pruin,     P8_25(PIN_INPUT, 1))		/* prg1_pru1_gpi14 */
	BONE_PIN(P8_25, gpio,      P8_25(PIN_INPUT, 7))
	BONE_PIN(P8_25, gpio_pu,   P8_25(PIN_INPUT_PULLUP, 7))
	BONE_PIN(P8_25, gpio_pd,   P8_25(PIN_INPUT_PULLDOWN, 7))

	/* P8_26 (AC27) PRG0_PRU0_GPO8 (gpio0_51) AC27_PRG0_PWM2_A1 */
	BONE_PIN(P8_26, default,   P8_26(PIN_INPUT, 7))
	BONE_PIN(P8_26, pruout,    P8_26(PIN_OUTPUT, 0))	/* prg0_pru0_gpo8 */
	BONE_PIN(P8_26, pruin,     P8_26(PIN_INPUT, 1))		/* prg0_pru0_gpi8 */
	BONE_PIN(P8_26, gpio,      P8_26(PIN_INPUT, 7))
	BONE_PIN(P8_26, gpio_pu,   P8_26(PIN_INPUT_PULLUP, 7))
	BONE_PIN(P8_26, gpio_pd,   P8_26(PIN_INPUT_PULLDOWN, 7))

	/* P8_27 (AA28) PRG0_PRU1_GPO8 (gpio0_71) AA28_PRG0_PRU1_GPO8 */
	BONE_PIN(P8_27, default,   P8_27(PIN_INPUT, 7))
	BONE_PIN(P8_27, pruout,    P8_27(PIN_OUTPUT, 0))	/* prg0_pru1_gpo8 */
	BONE_PIN(P8_27, pruin,     P8_27(PIN_INPUT, 1))		/* prg0_pru1_gpi8 */
	BONE_PIN(P8_27, gpio,      P8_27(PIN_INPUT, 7))
	BONE_PIN(P8_27, gpio_pu,   P8_27(PIN_INPUT_PULLUP, 7))
	BONE_PIN(P8_27, gpio_pd,   P8_27(PIN_INPUT_PULLDOWN, 7))

	/* P8_28 (Y24) PRG0_PRU1_GPO9 (gpio0_72) Y24_PRG0_UART0_RXD */
	BONE_PIN(P8_28, default,   P8_28(PIN_INPUT, 7))
	BONE_PIN(P8_28, pruout,    P8_28(PIN_OUTPUT, 0))	/* prg0_pru1_gpo9 */
	BONE_PIN(P8_28, pruin,     P8_28(PIN_INPUT, 1))		/* prg0_pru1_gpi9 */
	BONE_PIN(P8_28, gpio,      P8_28(PIN_INPUT, 7))
	BONE_PIN(P8_28, gpio_pu,   P8_28(PIN_INPUT_PULLUP, 7))
	BONE_PIN(P8_28, gpio_pd,   P8_28(PIN_INPUT_PULLDOWN, 7))

	/* P8_29 (AA25) PRG0_PRU1_GPO10 (gpio0_73) AA25_PRG0_UART0_TXD */
	BONE_PIN(P8_29, default,   P8_29(PIN_INPUT, 7))
	BONE_PIN(P8_29, pruout,    P8_29(PIN_OUTPUT, 0))	/* prg0_pru1_gpo10 */
	BONE_PIN(P8_29, pruin,     P8_29(PIN_INPUT, 1))		/* prg0_pru1_gpi10 */
	BONE_PIN(P8_29, gpio,      P8_29(PIN_INPUT, 7))
	BONE_PIN(P8_29, gpio_pu,   P8_29(PIN_INPUT_PULLUP, 7))
	BONE_PIN(P8_29, gpio_pd,   P8_29(PIN_INPUT_PULLDOWN, 7))

	/* P8_30 (AG26) PRG0_PRU1_GPO11 (gpio0_74) AG26_PRG0_PRU1_GPO11 */
	BONE_PIN(P8_30, default,   P8_30(PIN_INPUT, 7))
	BONE_PIN(P8_30, pruout,    P8_30(PIN_OUTPUT, 0))	/* prg0_pru1_gpo11 */
	BONE_PIN(P8_30, pruin,     P8_30(PIN_INPUT, 1))		/* prg0_pru1_gpi11 */
	BONE_PIN(P8_30, gpio,      P8_30(PIN_INPUT, 7))
	BONE_PIN(P8_30, gpio_pu,   P8_30(PIN_INPUT_PULLUP, 7))
	BONE_PIN(P8_30, gpio_pd,   P8_30(PIN_INPUT_PULLDOWN, 7))

	/* P8_31 (AJ25/AE29) PRG1_PRU1_GPO11/PRG0_PRU1_GPO0 (gpio0_32/gpio0_63) AJ25_AE29 */
	BONE_PIN(P8_31, default,   P8_31A(PIN_INPUT, 7) P8_31B(PIN_INPUT, 7))
	BONE_PIN(P8_31, pruout,    P8_31A(PIN_OUTPUT, 0) P8_31B(PIN_INPUT, 7))
	BONE_PIN(P8_31, pruin,     P8_31A(PIN_INPUT, 1) P8_31B(PIN_INPUT, 7))
	BONE_PIN(P8_31, gpio,      P8_31A(PIN_INPUT, 7) P8_31B(PIN_INPUT, 7))	/* gpio0_32 */
	BONE_PIN(P8_31, gpio_pu,   P8_31A(PIN_INPUT_PULLUP, 7) P8_31B(PIN_INPUT, 7))
	BONE_PIN(P8_31, gpio_pd,   P8_31A(PIN_INPUT_PULLDOWN, 7) P8_31B(PIN_INPUT, 7))
	BONE_PIN(P8_31, qep,       P8_31A(PIN_INPUT, 9) P8_31B(PIN_INPUT, 7))	/* eqep1_i */
	BONE_PIN(P8_31, uart,      P8_31A(PIN_INPUT, 7) P8_31B(PIN_INPUT, 14))	/* uart5_rxd */

	/* P8_32 (AG21/AD28) PRG1_PRU1_GPO5/PRG0_PRU1_GPO1 (gpio0_26/gpio0_64) AG21_AD28 */
	BONE_PIN(P8_32, default,   P8_32A(PIN_INPUT, 7) P8_32B(PIN_INPUT, 7))
	BONE_PIN(P8_32, pruout,    P8_32A(PIN_OUTPUT, 0) P8_32B(PIN_INPUT, 7))
	BONE_PIN(P8_32, pruin,     P8_32A(PIN_INPUT, 1) P8_32B(PIN_INPUT, 7))
	BONE_PIN(P8_32, gpio,      P8_32A(PIN_INPUT, 7) P8_32B(PIN_INPUT, 7))	/* gpio0_26 */
	BONE_PIN(P8_32, gpio_pu,   P8_32A(PIN_INPUT_PULLUP, 7) P8_32B(PIN_INPUT, 7))
	BONE_PIN(P8_32, gpio_pd,   P8_32A(PIN_INPUT_PULLDOWN, 7) P8_32B(PIN_INPUT, 7))
	BONE_PIN(P8_32, qep,       P8_32A(PIN_INPUT, 9) P8_32B(PIN_INPUT, 7))	/* eqep1_s */
	BONE_PIN(P8_32, uart,      P8_32A(PIN_INPUT, 7) P8_32B(PIN_OUTPUT, 14))	/* uart5_txd */

	/* P8_33 (AH24/AA2) PRG1_PRU1_GPO4/SPI0_CS0 (gpio0_25/gpio0_111) AH24_AA2 */
	BONE_PIN(P8_33, default,   P8_33A(PIN_INPUT, 7) P8_33B(PIN_INPUT, 7))
	BONE_PIN(P8_33, pruout,    P8_33A(PIN_OUTPUT, 0) P8_33B(PIN_INPUT, 7))	/* prg1_pru1_gpo4 */
	BONE_PIN(P8_33, pruin,     P8_33A(PIN_INPUT, 1) P8_33B(PIN_INPUT, 7))	/* prg1_pru1_gpi4 */
	BONE_PIN(P8_33, gpio,      P8_33A(PIN_INPUT, 7) P8_33B(PIN_INPUT, 7))	/* gpio0_25 */
	BONE_PIN(P8_33, gpio_pu,   P8_33A(PIN_INPUT_PULLUP, 7) P8_33B(PIN_INPUT, 7))
	BONE_PIN(P8_33, gpio_pd,   P8_33A(PIN_INPUT_PULLDOWN, 7) P8_33B(PIN_INPUT, 7))
	BONE_PIN(P8_33, qep,       P8_33A(PIN_INPUT, 9) P8_33B(PIN_INPUT, 7))	/* eqep1_b */

	/* P8_34 (AD22) PRG1_PRU0_GPO6 (gpio0_7) AD22_UART2_TXD */
	BONE_PIN(P8_34, default,   P8_34(PIN_INPUT, 7))
	BONE_PIN(P8_34, pruout,    P8_34(PIN_OUTPUT, 0))	/* prg1_pru0_gpo6 */
	BONE_PIN(P8_34, pruin,     P8_34(PIN_INPUT, 1))		/* prg1_pru0_gpi6 */
	BONE_PIN(P8_34, gpio,      P8_34(PIN_INPUT, 7))
	BONE_PIN(P8_34, gpio_pu,   P8_34(PIN_INPUT_PULLUP, 7))
	BONE_PIN(P8_34, gpio_pd,   P8_34(PIN_INPUT_PULLDOWN, 7))
	BONE_PIN(P8_34, uart,      P8_34(PIN_OUTPUT, 14))	/* uart2_txd */

	/* P8_35 (AD23/Y3) PRG1_PRU1_GPO3/SPI1_CS0 (gpio0_24/gpio0_116) AD23_Y3 */
	BONE_PIN(P8_35, default,   P8_35A(PIN_INPUT, 7) P8_35B(PIN_INPUT, 7))
	BONE_PIN(P8_35, pruout,    P8_35A(PIN_OUTPUT, 0) P8_35B(PIN_INPUT, 7))	/* prg1_pru1_gpo3 */
	BONE_PIN(P8_35, pruin,     P8_35A(PIN_INPUT, 1) P8_35B(PIN_INPUT, 7))	/* prg1_pru1_gpi3 */
	BONE_PIN(P8_35, gpio,      P8_35A(PIN_INPUT, 7) P8_35B(PIN_INPUT, 7))	/* gpio0_24 */
	BONE_PIN(P8_35, gpio_pu,   P8_35A(PIN_INPUT_PULLUP, 7) P8_35B(PIN_INPUT, 7))
	BONE_PIN(P8_35, gpio_pd,   P8_35A(PIN_INPUT_PULLDOWN, 7) P8_35B(PIN_INPUT, 7))
	BONE_PIN(P8_35, qep,       P8_35A(PIN_INPUT, 9) P8_35B(PIN_INPUT, 7))	/* eqep1_a */
	BONE_PIN(P8_35, uart,      P8_35A(PIN_INPUT, 7) P8_35B(PIN_INPUT, 3))	/* uart5_rxd */

	/* P8_36 (AE20) PRG1_PRU0_GPO7 (gpio0_8) AE20_MCAN4_TX */
	BONE_PIN(P8_36, default,   P8_36(PIN_INPUT, 7))
	BONE_PIN(P8_36, pruout,    P8_36(PIN_OUTPUT, 0))	/* prg1_pru0_gpo7 */
	BONE_PIN(P8_36, pruin,     P8_36(PIN_INPUT, 1))		/* prg1_pru0_gpi7 */
	BONE_PIN(P8_36, can,       P8_36(PIN_OUTPUT, 6))	/* mcan4_tx */
	BONE_PIN(P8_36, gpio,      P8_36(PIN_INPUT, 7))
	BONE_PIN(P8_36, gpio_pu,   P8_36(PIN_INPUT_PULLUP, 7))
	BONE_PIN(P8_36, gpio_pd,   P8_36(PIN_INPUT_PULLDOWN, 7))

	/* P8_37 (Y27/AD21) RGMII6_RD2/PRG1_PRU0_GPO10 (gpio0_106/gpio0_11) Y27_AD21 */
	BONE_PIN(P8_37, default,   P8_37A(PIN_INPUT, 7) P8_37B(PIN_INPUT, 7))
	BONE_PIN(P8_37, pruout,    P8_37A(PIN_INPUT, 7) P8_37B(PIN_OUTPUT, 0))	/* prg1_pru0_gpo10 */
	BONE_PIN(P8_37, pruin,     P8_37A(PIN_INPUT, 7) P8_37B(PIN_INPUT, 1))	/* prg1_pru0_gpi10 */
	BONE_PIN(P8_37, gpio,      P8_37A(PIN_INPUT, 7) P8_37B(PIN_INPUT, 7))	/* gpio0_106 */
	BONE_PIN(P8_37, gpio_pu,   P8_37A(PIN_INPUT_PULLUP, 7) P8_37B(PIN_INPUT, 7))
	BONE_PIN(P8_37, gpio_pd,   P8_37A(PIN_INPUT_PULLDOWN, 7) P8_37B(PIN_INPUT, 7))
	BONE_PIN(P8_37, pwm,       P8_37A(PIN_OUTPUT, 6) P8_37B(PIN_INPUT, 7))	/* ehrpwm5_a */
	BONE_PIN(P8_37, spi,       P8_37A(PIN_INPUT, 7) P8_37B(PIN_OUTPUT, 4))	/* spi6_cs2 */
	BONE_PIN(P8_37, uart,      P8_37A(PIN_OUTPUT, 3) P8_37B(PIN_INPUT, 7))	/* uart5_txd */

	/* P8_38 (AJ20/Y29) PRG1_PRU0_GPO8/RGMII6_RD3 (gpio0_9/gpio0_105) Y29_AJ20 */
	BONE_PIN(P8_38, default,   P8_38A(PIN_INPUT, 7) P8_38B(PIN_INPUT, 7))
	BONE_PIN(P8_38, pruout,    P8_38A(PIN_OUTPUT, 0) P8_38B(PIN_INPUT, 7))	/* prg1_pru0_gpo8 */
	BONE_PIN(P8_38, pruin,     P8_38A(PIN_INPUT, 1) P8_38B(PIN_INPUT, 7))	/* prg1_pru0_gpi8 */
	BONE_PIN(P8_38, can,       P8_38A(PIN_INPUT, 6) P8_38B(PIN_INPUT, 7))	/* mcan4_rx */
	BONE_PIN(P8_38, gpio,      P8_38A(PIN_INPUT, 7) P8_38B(PIN_INPUT, 7))	/* gpio0_9 */
	BONE_PIN(P8_38, gpio_pu,   P8_38A(PIN_INPUT_PULLUP, 7) P8_38B(PIN_INPUT, 7))
	BONE_PIN(P8_38, gpio_pd,   P8_38A(PIN_INPUT_PULLDOWN, 7) P8_38B(PIN_INPUT, 7))
	BONE_PIN(P8_38, uart,      P8_38A(PIN_INPUT, 7) P8_38B(PIN_INPUT, 3))	/* uart5_rxd */

	/* P8_39 (AC26) PRG0_PRU1_GPO6 (gpio0_69) AC26_PRG0_PRU1_GPO6 */
	BONE_PIN(P8_39, default,   P8_39(PIN_INPUT, 7))
	BONE_PIN(P8_39, pruout,    P8_39(PIN_OUTPUT, 0))	/* prg0_pru1_gpo6 */
	BONE_PIN(P8_39, pruin,     P8_39(PIN_INPUT, 1))		/* prg0_pru1_gpi6 */
	BONE_PIN(P8_39, gpio,      P8_39(PIN_INPUT, 7))
	BONE_PIN(P8_39, gpio_pu,   P8_39(PIN_INPUT_PULLUP, 7))
	BONE_PIN(P8_39, gpio_pd,   P8_39(PIN_INPUT_PULLDOWN, 7))

	/* P8_40 (AA24) PRG0_PRU1_GPO7 (gpio0_70) AA24_PRG0_PRU1_GPO7 */
	BONE_PIN(P8_40, default,   P8_40(PIN_INPUT, 7))
	BONE_PIN(P8_40, pruout,    P8_40(PIN_OUTPUT, 0))	/* prg0_pru1_gpo7 */
	BONE_PIN(P8_40, pruin,     P8_40(PIN_INPUT, 1))		/* prg0_pru1_gpi7 */
	BONE_PIN(P8_40, gpio,      P8_40(PIN_INPUT, 7))
	BONE_PIN(P8_40, gpio_pu,   P8_40(PIN_INPUT_PULLUP, 7))
	BONE_PIN(P8_40, gpio_pd,   P8_40(PIN_INPUT_PULLDOWN, 7))
	BONE_PIN(P8_40, uart,      P8_40(PIN_OUTPUT, 14))	/* uart2_txd */

	/* P8_41 (AD29) PRG0_PRU1_GPO4 (gpio0_67) AD29_PRG0_PRU1_GPO4 */
	BONE_PIN(P8_41, default,   P8_41(PIN_INPUT, 7))
	BONE_PIN(P8_41, pruout,    P8_41(PIN_OUTPUT, 0))	/* prg0_pru1_gpo4 */
	BONE_PIN(P8_41, pruin,     P8_41(PIN_INPUT, 1))		/* prg0_pru1_gpi4 */
	BONE_PIN(P8_41, gpio,      P8_41(PIN_INPUT, 7))
	BONE_PIN(P8_41, gpio_pu,   P8_41(PIN_INPUT_PULLUP, 7))
	BONE_PIN(P8_41, gpio_pd,   P8_41(PIN_INPUT_PULLDOWN, 7))

	/* P8_42 (AB27) PRG0_PRU1_GPO5 (gpio0_68) AB27_SYS_BOOTMODE6 */
	BONE_PIN(P8_42, default,   P8_42(PIN_INPUT, 7))
	BONE_PIN(P8_42, pruout,    P8_42(PIN_OUTPUT, 0))	/* prg0_pru1_gpo5 */
	BONE_PIN(P8_42, pruin,     P8_42(PIN_INPUT, 1))		/* prg0_pru1_gpi5 */
	BONE_PIN(P8_42, gpio,      P8_42(PIN_INPUT, 7))
	BONE_PIN(P8_42, gpio_pu,   P8_42(PIN_INPUT_PULLUP, 7))
	BONE_PIN(P8_42, gpio_pd,   P8_42(PIN_INPUT_PULLDOWN, 7))

	/* P8_43 (AD27) PRG0_PRU1_GPO2 (gpio0_65) AD27_PRG0_PRU1_GPO2 */
	BONE_PIN(P8_43, default,   P8_43(PIN_INPUT, 7))
	BONE_PIN(P8_43, pruout,    P8_43(PIN_OUTPUT, 0))	/* prg0_pru1_gpo2 */
	BONE_PIN(P8_43, pruin,     P8_43(PIN_INPUT, 1))		/* prg0_pru1_gpi2 */
	BONE_PIN(P8_43, gpio,      P8_43(PIN_INPUT, 7))
	BONE_PIN(P8_43, gpio_pu,   P8_43(PIN_INPUT_PULLUP, 7))
	BONE_PIN(P8_43, gpio_pd,   P8_43(PIN_INPUT_PULLDOWN, 7))

	/* P8_44 (AC25) PRG0_PRU1_GPO3 (gpio0_66) AC25_PRG0_PRU1_GPO3 */
	BONE_PIN(P8_44, default,   P8_44(PIN_INPUT, 7))
	BONE_PIN(P8_44, pruout,    P8_44(PIN_OUTPUT, 0))	/* prg0_pru1_gpo3 */
	BONE_PIN(P8_44, pruin,     P8_44(PIN_INPUT, 1))		/* prg0_pru1_gpi3 */
	BONE_PIN(P8_44, gpio,      P8_44(PIN_INPUT, 7))
	BONE_PIN(P8_44, gpio_pu,   P8_44(PIN_INPUT_PULLUP, 7))
	BONE_PIN(P8_44, gpio_pd,   P8_44(PIN_INPUT_PULLDOWN, 7))

	/* P8_45 (AG29) PRG0_PRU1_GPO16 (gpio0_79) AG29_PRG0_PRU1_GPO16 */
	BONE_PIN(P8_45, default,   P8_45(PIN_INPUT, 7))
	BONE_PIN(P8_45, pruout,    P8_45(PIN_OUTPUT, 0))	/* prg0_pru1_gpo16 */
	BONE_PIN(P8_45, pruin,     P8_45(PIN_INPUT, 1))		/* prg0_pru1_gpi16 */
	BONE_PIN(P8_45, gpio,      P8_45(PIN_INPUT, 7))
	BONE_PIN(P8_45, gpio_pu,   P8_45(PIN_INPUT_PULLUP, 7))
	BONE_PIN(P8_45, gpio_pd,   P8_45(PIN_INPUT_PULLDOWN, 7))

	/* P8_46 (Y25) PRG0_PRU1_GPO17 (gpio0_80) Y25_SYS_BOOTMODE3 */
	BONE_PIN(P8_46, default,   P8_46(PIN_INPUT, 7))
	BONE_PIN(P8_46, pruout,    P8_46(PIN_OUTPUT, 0))	/* prg0_pru1_gpo17 */
	BONE_PIN(P8_46, pruin,     P8_46(PIN_INPUT, 1))		/* prg0_pru1_gpi17 */
	BONE_PIN(P8_46, gpio,      P8_46(PIN_INPUT, 7))
	BONE_PIN(P8_46, gpio_pu,   P8_46(PIN_INPUT_PULLUP, 7))
	BONE_PIN(P8_46, gpio_pd,   P8_46(PIN_INPUT_PULLDOWN, 7))

	/* Full P9 header mode definitions */
	/* P9_01 - GND */
	/* P9_02 - GND */
	/* P9_03 - VOUT_3V3 */
	/* P9_04 - VOUT_3V3 */
	/* P9_05 - VIN */
	/* P9_06 - VIN */
	/* P9_07 - VOUT_SYS */
	/* P9_08 - VOUT_SYS */
	/* P9_09 - RESET# */
	/* P9_10 - POWER# */

	/* P9_11 (AC23) PRG1_PRU0_GPO0 (gpio0_1) AC23_UART0_RXD */
	BONE_PIN(P9_11, default,   P9_11(PIN_INPUT, 7))
	BONE_PIN(P9_11, pruout,    P9_11(PIN_OUTPUT, 0))	/* prg1_pru0_gpo0 */
	BONE_PIN(P9_11, pruin,     P9_11(PIN_INPUT, 1))		/* prg1_pru0_gpi0 */
	BONE_PIN(P9_11, gpio,      P9_11(PIN_INPUT, 7))
	BONE_PIN(P9_11, gpio_pu,   P9_11(PIN_INPUT_PULLUP, 7))
	BONE_PIN(P9_11, gpio_pd,   P9_11(PIN_INPUT_PULLDOWN, 7))
	BONE_PIN(P9_11, uart,      P9_11(PIN_INPUT, 14))	/* uart0_rxd */

	/* P9_12 (AE27) PRG0_PRU0_GPO2 (gpio0_45) AE27_MCASP0_ACLKR */
	BONE_PIN(P9_12, default,   P9_12(PIN_INPUT, 7))
	BONE_PIN(P9_12, pruout,    P9_12(PIN_OUTPUT, 0))	/* prg0_pru0_gpo2 */
	BONE_PIN(P9_12, pruin,     P9_12(PIN_INPUT, 1))		/* prg0_pru0_gpi2 */
	BONE_PIN(P9_12, gpio,      P9_12(PIN_INPUT, 7))
	BONE_PIN(P9_12, gpio_pu,   P9_12(PIN_INPUT_PULLUP, 7))
	BONE_PIN(P9_12, gpio_pd,   P9_12(PIN_INPUT_PULLDOWN, 7))

	/* P9_13 (AG22) PRG1_PRU0_GPO1 (gpio0_2) AG22_UART0_TXD */
	BONE_PIN(P9_13, default,   P9_13(PIN_INPUT, 7))
	BONE_PIN(P9_13, pruout,    P9_13(PIN_OUTPUT, 0))	/* prg1_pru0_gpo1 */
	BONE_PIN(P9_13, pruin,     P9_13(PIN_INPUT, 1))		/* prg1_pru0_gpi1 */
	BONE_PIN(P9_13, gpio,      P9_13(PIN_INPUT, 7))
	BONE_PIN(P9_13, gpio_pu,   P9_13(PIN_INPUT_PULLUP, 7))
	BONE_PIN(P9_13, gpio_pd,   P9_13(PIN_INPUT_PULLDOWN, 7))
	BONE_PIN(P9_13, uart,      P9_13(PIN_OUTPUT, 14))	/* uart0_txd */

	/* P9_14 (U27) RGMII5_RD3 (gpio0_93) U27_EHRPWM2_A */
	BONE_PIN(P9_14, default,   P9_14(PIN_INPUT, 7))
	BONE_PIN(P9_14, gpio,      P9_14(PIN_INPUT, 7))
	BONE_PIN(P9_14, gpio_pu,   P9_14(PIN_INPUT_PULLUP, 7))
	BONE_PIN(P9_14, gpio_pd,   P9_14(PIN_INPUT_PULLDOWN, 7))
	BONE_PIN(P9_14, pwm,       P9_14(PIN_OUTPUT, 6))	/* ehrpwm2_a */

	/* P9_15 (AD25) PRG0_PRU0_GPO4 (gpio0_47) AD25_PRG0_PRU0_GPO4 */
	BONE_PIN(P9_15, default,   P9_15(PIN_INPUT, 7))
	BONE_PIN(P9_15, pruout,    P9_15(PIN_OUTPUT, 0))	/* prg0_pru0_gpo4 */
	BONE_PIN(P9_15, pruin,     P9_15(PIN_INPUT, 1))		/* prg0_pru0_gpi4 */
	BONE_PIN(P9_15, gpio,      P9_15(PIN_INPUT, 7))
	BONE_PIN(P9_15, gpio_pu,   P9_15(PIN_INPUT_PULLUP, 7))
	BONE_PIN(P9_15, gpio_pd,   P9_15(PIN_INPUT_PULLDOWN, 7))

	/* P9_16 (U24) RGMII5_RD2 (gpio0_94) U24_EHRPWM2_B */
	BONE_PIN(P9_16, default,   P9_16(PIN_INPUT, 7))
	BONE_PIN(P9_16, pruout,    P9_16(PIN_OUTPUT, 0))
	BONE_PIN(P9_16, pruin,     P9_16(PIN_INPUT, 1))
	BONE_PIN(P9_16, gpio,      P9_16(PIN_INPUT, 7))
	BONE_PIN(P9_16, gpio_pu,   P9_16(PIN_INPUT_PULLUP, 7))
	BONE_PIN(P9_16, gpio_pd,   P9_16(PIN_INPUT_PULLDOWN, 7))
	BONE_PIN(P9_16, pwm,       P9_16(PIN_OUTPUT, 6))	/* ehrpwm2_b */

	/* P9_17 (AC21/AA3) PRG1_PRU1_GPO7/SPI0_D1 (gpio0_28/gpio0_115) AC21_AA3 */
	BONE_PIN(P9_17, default,   P9_17A(PIN_INPUT, 7) P9_17B(PIN_INPUT, 7))
	BONE_PIN(P9_17, pruout,    P9_17A(PIN_OUTPUT, 0) P9_17B(PIN_INPUT, 7))	/* prg1_pru1_gpo7 */
	BONE_PIN(P9_17, pruin,     P9_17A(PIN_INPUT, 1) P9_17B(PIN_INPUT, 7))	/* prg1_pru1_gpi7 */
	BONE_PIN(P9_17, gpio,      P9_17A(PIN_INPUT, 7) P9_17B(PIN_INPUT, 7))	/* gpio0_28 */
	BONE_PIN(P9_17, gpio_pu,   P9_17A(PIN_INPUT_PULLUP, 7) P9_17B(PIN_INPUT, 7))
	BONE_PIN(P9_17, gpio_pd,   P9_17A(PIN_INPUT_PULLDOWN, 7) P9_17B(PIN_INPUT, 7))
	BONE_PIN(P9_17, i2c,       P9_17A(PIN_INPUT, 7) P9_17B(PIN_INPUT_PULLUP, 2))	/* i2c6_scl */
	BONE_PIN(P9_17, spi,       P9_17A(PIN_OUTPUT, 4) P9_17B(PIN_INPUT, 7))	/* spi6_cs0 */

	/* P9_18 (AH22/Y2) PRG1_PRU1_GPO19/SPI1_D1 (gpio0_40/gpio0_120) AH22_Y2 */
	BONE_PIN(P9_18, default,   P9_18A(PIN_INPUT, 7) P9_18B(PIN_INPUT, 7))
	BONE_PIN(P9_18, pruout,    P9_18A(PIN_OUTPUT, 0) P9_18B(PIN_INPUT, 7))	/* prg1_pru1_gpo19 */
	BONE_PIN(P9_18, pruin,     P9_18A(PIN_INPUT, 1) P9_18B(PIN_INPUT, 7))	/* prg1_pru1_gpi19 */
	BONE_PIN(P9_18, gpio,      P9_18A(PIN_INPUT, 7) P9_18B(PIN_INPUT, 7))	/* gpio0_40 */
	BONE_PIN(P9_18, gpio_pu,   P9_18A(PIN_INPUT_PULLUP, 7) P9_18B(PIN_INPUT, 7))
	BONE_PIN(P9_18, gpio_pd,   P9_18A(PIN_INPUT_PULLDOWN, 7) P9_18B(PIN_INPUT, 7))
	BONE_PIN(P9_18, i2c,       P9_18A(PIN_INPUT, 7) P9_18B(PIN_INPUT_PULLUP, 2))	/* i2c6_sda */
	BONE_PIN(P9_18, spi,       P9_18A(PIN_OUTPUT, 4) P9_18B(PIN_INPUT, 7))	/* spi6_d1 */

	/* P9_19 (W5/AF29) MCAN0_RX/PRG0_PRU1_GPO15 (gpio1_1/gpio0_78) W5_AF29 */
	BONE_PIN(P9_19, default,   P9_19A(PIN_INPUT, 7) P9_19B(PIN_INPUT, 7))
	BONE_PIN(P9_19, pruout,    P9_19A(PIN_INPUT, 7) P9_19B(PIN_OUTPUT, 0))	/* prg0_pru1_gpo15 */
	BONE_PIN(P9_19, pruin,     P9_19A(PIN_INPUT, 7) P9_19B(PIN_INPUT, 1))	/* prg0_pru1_gpi15 */
	BONE_PIN(P9_19, can,       P9_19A(PIN_INPUT, 0) P9_19B(PIN_INPUT, 7))	/* mcan0_rx */
	BONE_PIN(P9_19, gpio,      P9_19A(PIN_INPUT, 7) P9_19B(PIN_INPUT, 7))	/* gpio1_1 */
	BONE_PIN(P9_19, gpio_pu,   P9_19A(PIN_INPUT_PULLUP, 7) P9_19B(PIN_INPUT, 7))
	BONE_PIN(P9_19, gpio_pd,   P9_19A(PIN_INPUT_PULLDOWN, 7) P9_19B(PIN_INPUT, 7))
	BONE_PIN(P9_19, i2c,       P9_19A(PIN_INPUT_PULLUP, 4) P9_19B(PIN_INPUT, 7))	/* i2c2_scl */

	/* P9_20 (W6/AE25) MCAN0_TX/PRG0_PRU1_GPO14 (gpio1_2/gpio0_77) W6_AE25 */
	BONE_PIN(P9_20, default,   P9_20A(PIN_INPUT, 7) P9_20B(PIN_INPUT, 7))
	BONE_PIN(P9_20, pruout,    P9_20A(PIN_INPUT, 7) P9_20B(PIN_OUTPUT, 0))	/* prg0_pru1_gpo14 */
	BONE_PIN(P9_20, pruin,     P9_20A(PIN_INPUT, 7) P9_20B(PIN_INPUT, 1))	/* prg0_pru1_gpi14 */
	BONE_PIN(P9_20, can,       P9_20A(PIN_OUTPUT, 0) P9_20B(PIN_INPUT, 7))	/* mcan0_tx */
	BONE_PIN(P9_20, gpio,      P9_20A(PIN_INPUT, 7) P9_20B(PIN_INPUT, 7))	/* gpio1_2 */
	BONE_PIN(P9_20, gpio_pu,   P9_20A(PIN_INPUT_PULLUP, 7) P9_20B(PIN_INPUT, 7))
	BONE_PIN(P9_20, gpio_pd,   P9_20A(PIN_INPUT_PULLDOWN, 7) P9_20B(PIN_INPUT, 7))
	BONE_PIN(P9_20, i2c,       P9_20A(PIN_INPUT_PULLUP, 4) P9_20B(PIN_INPUT, 7))	/* i2c2_sda */

	/* P9_21 (AJ22/U28) PRG1_PRU1_GPO18/RGMII5_TD0 (gpio0_39/gpio0_90) AJ22_U28 */
	BONE_PIN(P9_21, default,   P9_21A(PIN_INPUT, 7) P9_21B(PIN_INPUT, 7))
	BONE_PIN(P9_21, pruout,    P9_21A(PIN_OUTPUT, 0) P9_21B(PIN_INPUT, 7))	/* prg1_pru1_gpo18 */
	BONE_PIN(P9_21, pruin,     P9_21A(PIN_INPUT, 1) P9_21B(PIN_INPUT, 7))	/* prg1_pru1_gpi18 */
	BONE_PIN(P9_21, gpio,      P9_21A(PIN_INPUT, 7) P9_21B(PIN_INPUT, 7))	/* gpio0_39 */
	BONE_PIN(P9_21, gpio_pu,   P9_21A(PIN_INPUT_PULLUP, 7) P9_21B(PIN_INPUT, 7))
	BONE_PIN(P9_21, gpio_pd,   P9_21A(PIN_INPUT_PULLDOWN, 7) P9_21B(PIN_INPUT, 7))
	BONE_PIN(P9_21, pwm,       P9_21A(PIN_INPUT, 7) P9_21B(PIN_OUTPUT, 6))	/* ehrpwm1_a */
	BONE_PIN(P9_21, spi,       P9_21A(PIN_OUTPUT, 4) P9_21B(PIN_INPUT, 7))	/* spi6_d0 */

	/* P9_22 (AC22/U29) PRG1_PRU1_GPO17/RGMII5_TXC (gpio0_38/gpio0_91) AC22_U29 */
	BONE_PIN(P9_22, default,   P9_22A(PIN_INPUT, 7) P9_22B(PIN_INPUT, 7))
	BONE_PIN(P9_22, pruout,    P9_22A(PIN_OUTPUT, 0) P9_22B(PIN_INPUT, 7))	/* prg1_pru1_gpo17 */
	BONE_PIN(P9_22, pruin,     P9_22A(PIN_INPUT, 1) P9_22B(PIN_INPUT, 7))	/* prg1_pru1_gpi17 */
	BONE_PIN(P9_22, gpio,      P9_22A(PIN_INPUT, 7) P9_22B(PIN_INPUT, 7))	/* gpio0_38 */
	BONE_PIN(P9_22, gpio_pu,   P9_22A(PIN_INPUT_PULLUP, 7) P9_22B(PIN_INPUT, 7))
	BONE_PIN(P9_22, gpio_pd,   P9_22A(PIN_INPUT_PULLDOWN, 7) P9_22B(PIN_INPUT, 7))
	BONE_PIN(P9_22, i2c,       P9_22A(PIN_INPUT, 7) P9_22B(PIN_INPUT_PULLUP, 2))	/* i2c6_scl */
	BONE_PIN(P9_22, pwm,       P9_22A(PIN_INPUT, 7) P9_22B(PIN_OUTPUT, 6))	/* ehrpwm1_b */
	BONE_PIN(P9_22, spi,       P9_22A(PIN_OUTPUT, 4) P9_22B(PIN_INPUT, 7))	/* spi6_clk */

	/* P9_23 (AG20) PRG1_PRU0_GPO9 (gpio0_10) AG20_SPI6_CS1 */
	BONE_PIN(P9_23, default,   P9_23(PIN_INPUT, 7))
	BONE_PIN(P9_23, pruout,    P9_23(PIN_OUTPUT, 0))	/* prg1_pru0_gpo9 */
	BONE_PIN(P9_23, pruin,     P9_23(PIN_INPUT, 1))		/* prg1_pru0_gpi9 */
	BONE_PIN(P9_23, gpio,      P9_23(PIN_INPUT, 7))
	BONE_PIN(P9_23, gpio_pu,   P9_23(PIN_INPUT_PULLUP, 7))
	BONE_PIN(P9_23, gpio_pd,   P9_23(PIN_INPUT_PULLDOWN, 7))
	BONE_PIN(P9_23, spi,       P9_23(PIN_OUTPUT, 4))	/* spi6_cs1 */

	/* P9_24 (Y5/AJ24) SPI1_D0/PRG1_PRU0_GPO12 (gpio0_119/gpio0_13) Y5_AJ24 */
	BONE_PIN(P9_24, default,   P9_24A(PIN_INPUT, 7) P9_24B(PIN_INPUT, 7))
	BONE_PIN(P9_24, pruout,    P9_24A(PIN_INPUT, 7) P9_24B(PIN_OUTPUT, 0))	/* prg1_pru0_gpo12 */
	BONE_PIN(P9_24, pruin,     P9_24A(PIN_INPUT, 7) P9_24B(PIN_INPUT, 1))	/* prg1_pru0_gpi12 */
	BONE_PIN(P9_24, can,       P9_24A(PIN_INPUT, 7) P9_24B(PIN_INPUT, 6) )	/* mcan4_rx */
	BONE_PIN(P9_24, gpio,      P9_24A(PIN_INPUT, 7) P9_24B(PIN_INPUT, 7))	/* gpio0_119 */
	BONE_PIN(P9_24, gpio_pu,   P9_24A(PIN_INPUT_PULLUP, 7) P9_24B(PIN_INPUT, 7))
	BONE_PIN(P9_24, gpio_pd,   P9_24A(PIN_INPUT_PULLDOWN, 7) P9_24B(PIN_INPUT, 7))
	BONE_PIN(P9_24, i2c,       P9_24A(PIN_INPUT_PULLUP, 2) P9_24B(PIN_INPUT, 7))	/* i2c4_scl */
	BONE_PIN(P9_24, uart,      P9_24A(PIN_OUTPUT, 3) P9_24B(PIN_INPUT, 7))	/* uart2_txd */

	/* P9_25 (AC4/W26) UART1_CTSn/RGMII6_RXC (gpio0_127/gpio0_104) AC4_W26 */
	BONE_PIN(P9_25, default,   P9_25A(PIN_INPUT, 7) P9_25B(PIN_INPUT, 7))
	BONE_PIN(P9_25, gpio,      P9_25A(PIN_INPUT, 7) P9_25B(PIN_INPUT, 7))	/* gpio0_127 */
	BONE_PIN(P9_25, gpio_pu,   P9_25A(PIN_INPUT_PULLUP, 7) P9_25B(PIN_INPUT, 7))
	BONE_PIN(P9_25, gpio_pd,   P9_25A(PIN_INPUT_PULLDOWN, 7) P9_25B(PIN_INPUT, 7))
	BONE_PIN(P9_25, pwm,       P9_25A(PIN_INPUT, 7) P9_25B(PIN_OUTPUT, 6))	/* ehrpwm4_b */
	BONE_PIN(P9_25, qep,       P9_25A(PIN_INPUT, 5) P9_25B(PIN_INPUT, 7))	/* eqep0_s */

	/* P9_26 (Y1/AF24) SPI1_CLK/PRG1_PRU0_GPO11 (gpio0_118/gpio0_12) Y1_AF24 */
	BONE_PIN(P9_26, default,   P9_26A(PIN_INPUT, 7) P9_26B(PIN_INPUT, 7))
	BONE_PIN(P9_26, pruout,    P9_26A(PIN_INPUT, 7) P9_26B(PIN_OUTPUT, 0))	/* prg1_pru0_gpo11 */
	BONE_PIN(P9_26, pruin,     P9_26A(PIN_INPUT, 7) P9_26B(PIN_INPUT, 1))	/* prg1_pru0_gpi11 */
	BONE_PIN(P9_26, can,       P9_26A(PIN_INPUT, 7) P9_26B(PIN_OUTPUT, 6) )	/* mcan4_tx */
	BONE_PIN(P9_26, gpio,      P9_26A(PIN_INPUT, 7) P9_26B(PIN_INPUT, 7))	/* gpio0_118 */
	BONE_PIN(P9_26, gpio_pu,   P9_26A(PIN_INPUT_PULLUP, 7) P9_26B(PIN_INPUT, 7))
	BONE_PIN(P9_26, gpio_pd,   P9_26A(PIN_INPUT_PULLDOWN, 7) P9_26B(PIN_INPUT, 7))
	BONE_PIN(P9_26, i2c,       P9_26A(PIN_INPUT_PULLUP, 2) P9_26B(PIN_INPUT, 7))	/* i2c4_sda */
	BONE_PIN(P9_26, uart,      P9_26A(PIN_INPUT, 3) P9_26B(PIN_INPUT, 7))	/* uart2_rxd */

	/* P9_27 (AD26/AB1) PRG0_PRU0_GPO3/UART0_RTSn (gpio0_46/gpio0_124) AD26_AB1 */
	BONE_PIN(P9_27, default,   P9_27A(PIN_INPUT, 7) P9_27B(PIN_INPUT, 7))
	BONE_PIN(P9_27, pruout,    P9_27A(PIN_OUTPUT, 0) P9_27B(PIN_INPUT, 7))	/* prg0_pru0_gpo3 */
	BONE_PIN(P9_27, pruin,     P9_27A(PIN_INPUT, 1) P9_27B(PIN_INPUT, 7))	/* prg0_pru0_gpi3 */
	BONE_PIN(P9_27, gpio,      P9_27A(PIN_INPUT, 7) P9_27B(PIN_INPUT, 7))	/* gpio0_46 */
	BONE_PIN(P9_27, gpio_pu,   P9_27A(PIN_INPUT_PULLUP, 7) P9_27B(PIN_INPUT, 7))
	BONE_PIN(P9_27, gpio_pd,   P9_27A(PIN_INPUT_PULLDOWN, 7) P9_27B(PIN_INPUT, 7))
	BONE_PIN(P9_27, qep,       P9_27A(PIN_INPUT, 7) P9_27B(PIN_INPUT, 5))	/* eqep0_b */

	/* P9_28 (U2/AF28) ECAP0_IN_APWM_OUT/PRG0_PRU0_GPO0 (gpio1_11/gpio0_43) U2_AF28 */
	BONE_PIN(P9_28, default,   P9_28A(PIN_INPUT, 7) P9_28B(PIN_INPUT, 7))
	BONE_PIN(P9_28, pruout,    P9_28A(PIN_INPUT, 7) P9_28B(PIN_OUTPUT, 0))	/* prg0_pru0_gpo0 */
	BONE_PIN(P9_28, pruin,     P9_28A(PIN_INPUT, 7) P9_28B(PIN_INPUT, 1))	/* prg0_pru0_gpi0 */
	BONE_PIN(P9_28, gpio,      P9_28A(PIN_INPUT, 7) P9_28B(PIN_INPUT, 7))	/* gpio1_11 */
	BONE_PIN(P9_28, gpio_pu,   P9_28A(PIN_INPUT_PULLUP, 7) P9_28B(PIN_INPUT, 7))
	BONE_PIN(P9_28, gpio_pd,   P9_28A(PIN_INPUT_PULLDOWN, 7) P9_28B(PIN_INPUT, 7))
	BONE_PIN(P9_28, spi,       P9_28A(PIN_OUTPUT, 6) P9_28B(PIN_INPUT, 7))	/* spi7_cs0 */

	/* P9_29 (V5/AB25) TIMER_IO1/PRG0_PRU0_GPO10 (gpio1_14/gpio0_53) V5_AB25 */
	BONE_PIN(P9_29, default,   P9_29A(PIN_INPUT, 7) P9_29B(PIN_INPUT, 7))
	BONE_PIN(P9_29, pruout,    P9_29A(PIN_INPUT, 7) P9_29B(PIN_OUTPUT, 0))	/* prg0_pru0_gpo10 */
	BONE_PIN(P9_29, pruin,     P9_29A(PIN_INPUT, 7) P9_29B(PIN_INPUT, 1))	/* prg0_pru0_gpi10 */
	BONE_PIN(P9_29, gpio,      P9_29A(PIN_INPUT, 7) P9_29B(PIN_INPUT, 7))	/* gpio1_14 */
	BONE_PIN(P9_29, gpio_pu,   P9_29A(PIN_INPUT_PULLUP, 7) P9_29B(PIN_INPUT, 7))
	BONE_PIN(P9_29, gpio_pd,   P9_29A(PIN_INPUT_PULLDOWN, 7) P9_29B(PIN_INPUT, 7))
	BONE_PIN(P9_29, spi,       P9_29A(PIN_OUTPUT, 6) P9_29B(PIN_INPUT, 7))	/* spi7_d1 */

	/* P9_30 (V6/AE28) TIMER_IO0/PRG0_PRU0_GPO1 (gpio1_13/gpio0_44) V6_AE28 */
	BONE_PIN(P9_30, default,   P9_30A(PIN_INPUT, 7) P9_30B(PIN_INPUT, 7))
	BONE_PIN(P9_30, pruout,    P9_30A(PIN_INPUT, 7) P9_30B(PIN_OUTPUT, 0))	/* prg0_pru0_gpo1 */
	BONE_PIN(P9_30, pruin,     P9_30A(PIN_INPUT, 7) P9_30B(PIN_INPUT, 1))	/* prg0_pru0_gpi1 */
	BONE_PIN(P9_30, gpio,      P9_30A(PIN_INPUT, 7) P9_30B(PIN_INPUT, 7))	/* gpio1_13 */
	BONE_PIN(P9_30, gpio_pu,   P9_30A(PIN_INPUT_PULLUP, 7) P9_30B(PIN_INPUT, 7))
	BONE_PIN(P9_30, gpio_pd,   P9_30A(PIN_INPUT_PULLDOWN, 7) P9_30B(PIN_INPUT, 7))
	BONE_PIN(P9_30, spi,       P9_30A(PIN_OUTPUT, 6) P9_30B(PIN_INPUT, 7))	/* spi7_d0 */

	/* P9_31 (U3/AB26) EXT_REFCLK1/PRG0_PRU0_GPO9 (gpio1_12/gpio0_52) U3_AB26 */
	BONE_PIN(P9_31, default,   P9_31A(PIN_INPUT, 7) P9_31B(PIN_INPUT, 7))
	BONE_PIN(P9_31, pruout,    P9_31A(PIN_INPUT, 7) P9_31B(PIN_OUTPUT, 0))	/* prg0_pru0_gpo9 */
	BONE_PIN(P9_31, pruin,     P9_31A(PIN_INPUT, 7) P9_31B(PIN_INPUT, 1))	/* prg0_pru0_gpi9 */
	BONE_PIN(P9_31, gpio,      P9_31A(PIN_INPUT, 7) P9_31B(PIN_INPUT, 7))	/* gpio1_12 */
	BONE_PIN(P9_31, gpio_pu,   P9_31A(PIN_INPUT_PULLUP, 7) P9_31B(PIN_INPUT, 7))
	BONE_PIN(P9_31, gpio_pd,   P9_31A(PIN_INPUT_PULLDOWN, 7) P9_31B(PIN_INPUT, 7))
	BONE_PIN(P9_31, spi,       P9_31A(PIN_OUTPUT, 6) P9_31B(PIN_INPUT, 7))	/* spi7_clk */

	/* P9_32 - ADC_REF_OUT */

	/* P9_33 (K24/AC28) MCU_ADC0_AIN4/PRG0_PRU0_GPO7 (gpio0_50) K24_AC28 */
	BONE_PIN(P9_33, default,   P9_33B(PIN_INPUT, 7))
	BONE_PIN(P9_33, pruout,    P9_33B(PIN_OUTPUT, 0))	/* prg0_pru0_gpo7 */
	BONE_PIN(P9_33, pruin,     P9_33B(PIN_INPUT, 1))	/* prg0_pru0_gpi7 */
	BONE_PIN(P9_33, gpio,      P9_33B(PIN_INPUT, 7))
	BONE_PIN(P9_33, gpio_pu,   P9_33B(PIN_INPUT_PULLUP, 7))
	BONE_PIN(P9_33, gpio_pd,   P9_33B(PIN_INPUT_PULLDOWN, 7))

	/* P9_34 - ADC_GND */

	/* P9_35 (K29/AH27) MCU_ADC0_AIN6/PRG0_PRU0_GPO12 (gpio0_55) K29_AH27 */
	BONE_PIN(P9_35, default,   P9_35B(PIN_INPUT, 7))
	BONE_PIN(P9_35, pruout,    P9_35B(PIN_OUTPUT, 0))	/* prg0_pru0_gpo12 */
	BONE_PIN(P9_35, pruin,     P9_35B(PIN_INPUT, 1))	/* prg0_pru0_gpi12 */
	BONE_PIN(P9_35, gpio,      P9_35B(PIN_INPUT, 7))
	BONE_PIN(P9_35, gpio_pu,   P9_35B(PIN_INPUT_PULLUP, 7))
	BONE_PIN(P9_35, gpio_pd,   P9_35B(PIN_INPUT_PULLDOWN, 7))

	/* P9_36 (K27/AH29) MCU_ADC0_AIN5/PRG0_PRU0_GPO13 (gpio0_56) K27_AH29 */
	BONE_PIN(P9_36, default,   P9_36B(PIN_INPUT, 7))
	BONE_PIN(P9_36, pruout,    P9_36B(PIN_OUTPUT, 0))	/* prg0_pru0_gpo13 */
	BONE_PIN(P9_36, pruin,     P9_36B(PIN_INPUT, 1))	/* prg0_pru0_gpi13 */
	BONE_PIN(P9_36, gpio,      P9_36B(PIN_INPUT, 7))
	BONE_PIN(P9_36, gpio_pu,   P9_36B(PIN_INPUT_PULLUP, 7))
	BONE_PIN(P9_36, gpio_pd,   P9_36B(PIN_INPUT_PULLDOWN, 7))

	/* P9_37 (K28/AG28) MCU_ADC0_AIN2/PRG0_PRU0_GPO14 (gpio0_57) K28_AG28 */
	BONE_PIN(P9_37, default,   P9_37B(PIN_INPUT, 7))
	BONE_PIN(P9_37, pruout,    P9_37B(PIN_OUTPUT, 0))	/* prg0_pru0_gpo14 */
	BONE_PIN(P9_37, pruin,     P9_37B(PIN_INPUT, 1))	/* prg0_pru0_gpi14 */
	BONE_PIN(P9_37, gpio,      P9_37B(PIN_INPUT, 7))
	BONE_PIN(P9_37, gpio_pu,   P9_37B(PIN_INPUT_PULLUP, 7))
	BONE_PIN(P9_37, gpio_pd,   P9_37B(PIN_INPUT_PULLDOWN, 7))

	/* P9_38 (L28/AG27) MCU_ADC0_AIN3/PRG0_PRU0_GPO15 (gpio0_58) L28_AG27 */
	BONE_PIN(P9_38, default,   P9_38B(PIN_INPUT, 7))
	BONE_PIN(P9_38, pruout,    P9_38B(PIN_OUTPUT, 0))	/* prg0_pru0_gpo15 */
	BONE_PIN(P9_38, pruin,     P9_38B(PIN_INPUT, 1))	/* prg0_pru0_gpi15 */
	BONE_PIN(P9_38, gpio,      P9_38B(PIN_INPUT, 7))
	BONE_PIN(P9_38, gpio_pu,   P9_38B(PIN_INPUT_PULLUP, 7))
	BONE_PIN(P9_38, gpio_pd,   P9_38B(PIN_INPUT_PULLDOWN, 7))

	/* P9_39 (K25/AJ28) MCU_ADC0_AIN0/PRG0_PRU0_GPO11 (gpio0_54) K25_AJ28 */
	BONE_PIN(P9_39, default,   P9_39B(PIN_INPUT, 7))
	BONE_PIN(P9_39, pruout,    P9_39B(PIN_OUTPUT, 0))	/* prg0_pru0_gpo11 */
	BONE_PIN(P9_39, pruin,     P9_39B(PIN_INPUT, 1))	/* prg0_pru0_gpi11 */
	BONE_PIN(P9_39, gpio,      P9_39B(PIN_INPUT, 7))
	BONE_PIN(P9_39, gpio_pu,   P9_39B(PIN_INPUT_PULLUP, 7))
	BONE_PIN(P9_39, gpio_pd,   P9_39B(PIN_INPUT_PULLDOWN, 7))

	/* P9_40 (K26/AA26) MCU_ADC0_AIN1/PRG0_PRU1_GPO18 (gpio0_81) K26_AA26 */
	BONE_PIN(P9_40, default,   P9_40B(PIN_INPUT, 7))
	BONE_PIN(P9_40, pruout,    P9_40B(PIN_OUTPUT, 0))	/* prg0_pru1_gpo18 */
	BONE_PIN(P9_40, pruin,     P9_40B(PIN_INPUT, 1))	/* prg0_pru1_gpi18 */
	BONE_PIN(P9_40, gpio,      P9_40B(PIN_INPUT, 7))
	BONE_PIN(P9_40, gpio_pu,   P9_40B(PIN_INPUT_PULLUP, 7))
	BONE_PIN(P9_40, gpio_pd,   P9_40B(PIN_INPUT_PULLDOWN, 7))
	BONE_PIN(P9_40, uart,      P9_40B(PIN_INPUT, 14))	/* uart2_rxd */

	/* P9_41 (AD5) UART1_RTSn (gpio1_0) AD5_EQEP0_I */
	BONE_PIN(P9_41, default,   P9_41(PIN_INPUT, 7))
	BONE_PIN(P9_41, pruout,    P9_41(PIN_OUTPUT, 0))
	BONE_PIN(P9_41, pruin,     P9_41(PIN_INPUT, 1))
	BONE_PIN(P9_41, gpio,      P9_41(PIN_INPUT, 7))
	BONE_PIN(P9_41, gpio_pu,   P9_41(PIN_INPUT_PULLUP, 7))
	BONE_PIN(P9_41, gpio_pd,   P9_41(PIN_INPUT_PULLDOWN, 7))
	BONE_PIN(P9_41, qep,       P9_41(PIN_INPUT, 5))	/* eqep0_i */

	/* P9_42 (AC2/AJ21) UART0_CTSn/PRG1_PRU0_GPO17 (gpio0_123/gpio0_18) AC2_AJ21 */
	BONE_PIN(P9_42, default,   P9_42A(PIN_INPUT, 7) P9_42B(PIN_INPUT, 7))
	BONE_PIN(P9_42, pruout,    P9_42A(PIN_INPUT, 7) P9_42B(PIN_OUTPUT, 0))	/* prg1_pru0_gpo17 */
	BONE_PIN(P9_42, pruin,     P9_42A(PIN_INPUT, 7) P9_42B(PIN_INPUT, 1))	/* prg1_pru0_gpi17 */
	BONE_PIN(P9_42, can,       P9_42A(PIN_INPUT, 7) P9_42B(PIN_OUTPUT, 6) )	/* mcan5_tx */
	BONE_PIN(P9_42, gpio,      P9_42A(PIN_INPUT, 7) P9_42B(PIN_INPUT, 7))	/* gpio0_123 */
	BONE_PIN(P9_42, gpio_pu,   P9_42A(PIN_INPUT_PULLUP, 7) P9_42B(PIN_INPUT, 7))
	BONE_PIN(P9_42, gpio_pd,   P9_42A(PIN_INPUT_PULLDOWN, 7) P9_42B(PIN_INPUT, 7))
	BONE_PIN(P9_42, qep,       P9_42A(PIN_INPUT, 5) P9_42B(PIN_INPUT, 7))	/* eqep0_a */

	/* P9_43 - GND */
	/* P9_44 - GND */
	/* P9_45 - GND */
	/* P9_46 - GND */

	pcie1_rst_pins_default: pcie1-rst-pins-default {
		pinctrl-single,pins = <
			J721E_IOPAD(0x5c, PIN_INPUT, 7) /* (AG23) PRG1_PRU1_GPO1.GPIO0_22 */
		>;
	};

	ehrpwm0_pins_default: ehrpwm0_pins_default {
		pinctrl-single,pins = <
			J721E_IOPAD(0x164, PIN_OUTPUT, 6) /* (V29) RGMII5_TD2.EHRPWM0_A */
			J721E_IOPAD(0x168, PIN_OUTPUT, 6) /* (V27) RGMII5_TD1.EHRPWM0_B */
		>;
	};

	ehrpwm1_pins_default: ehrpwm1_pins_default {
		pinctrl-single,pins = <
			J721E_IOPAD(0x16c, PIN_OUTPUT, 6) /* (U28) RGMII5_TD0.EHRPWM1_A */
			J721E_IOPAD(0x170, PIN_OUTPUT, 6) /* (U29) RGMII5_TXC.EHRPWM1_B */
		>;
	};

	ehrpwm2_pins_default: ehrpwm2_pins_default {
		pinctrl-single,pins = <
			J721E_IOPAD(0x178, PIN_OUTPUT, 6) /* (U27) RGMII5_RD3.EHRPWM2_A */
			J721E_IOPAD(0x17c, PIN_OUTPUT, 6) /* (U24) RGMII5_RD2.EHRPWM2_B */
		>;
	};

	ehrpwm3_pins_default: ehrpwm3_pins_default {
		pinctrl-single,pins = <
			J721E_IOPAD(0x18c, PIN_OUTPUT, 6) /* (V23) RGMII6_RX_CTL.EHRPWM3_A */
			J721E_IOPAD(0x190, PIN_OUTPUT, 6) /* (W23) RGMII6_TD3.EHRPWM3_B */
		>;
	};

	ehrpwm4_pins_default: ehrpwm4_pins_default {
		pinctrl-single,pins = <
/*			J721E_IOPAD(0x1a0, PIN_OUTPUT, 6)*/ /* (W29) RGMII6_TXC.EHRPWM4_A */
			J721E_IOPAD(0x1a4, PIN_OUTPUT, 6) /* (W26) RGMII6_RXC.EHRPWM4_B */
		>;
	};

	ehrpwm5_pins_default: ehrpwm5_pins_default {
		pinctrl-single,pins = <
			J721E_IOPAD(0x1ac, PIN_OUTPUT, 6) /* (Y27) RGMII6_RD2.EHRPWM5_A */
/*			J721E_IOPAD(0x1b0, PIN_OUTPUT, 6)*/ /* (W24) RGMII6_RD1.EHRPWM5_B */
		>;
	};
};

&wkup_pmx0 {
	wkup_i2c0_pins_default: wkup-i2c0-pins-default {
		pinctrl-single,pins = <
			J721E_WKUP_IOPAD(0xf8, PIN_INPUT_PULLUP, 0) /* (J25) WKUP_I2C0_SCL */
			J721E_WKUP_IOPAD(0xfc, PIN_INPUT_PULLUP, 0) /* (H24) WKUP_I2C0_SDA */
		>;
	};

	eeprom_wp_pins_default: eeprom-wp-pins-default {
		pinctrl-single,pins = <
			J721E_WKUP_IOPAD(0xc4, PIN_OUTPUT_PULLUP, 7) /* (G24) WKUP_GPIO0_5 */
		>;
	};

	mcu_adc0_pins_default: mcu_adc0_pins_default {
		pinctrl-single,pins = <
			J721E_WKUP_IOPAD(0x130, PIN_INPUT, 0) /* (K25) MCU_ADC0_AIN0 */
			J721E_WKUP_IOPAD(0x134, PIN_INPUT, 0) /* (K26) MCU_ADC0_AIN1 */
			J721E_WKUP_IOPAD(0x138, PIN_INPUT, 0) /* (K28) MCU_ADC0_AIN2 */
			J721E_WKUP_IOPAD(0x13c, PIN_INPUT, 0) /* (L28) MCU_ADC0_AIN3 */
			J721E_WKUP_IOPAD(0x140, PIN_INPUT, 0) /* (K24) MCU_ADC0_AIN4 */
			J721E_WKUP_IOPAD(0x144, PIN_INPUT, 0) /* (K27) MCU_ADC0_AIN5 */ /* TODO: disable? */
			J721E_WKUP_IOPAD(0x148, PIN_INPUT, 0) /* (K29) MCU_ADC0_AIN6 */
		>;
	};

	mcu_adc1_pins_default: mcu_adc1_pins_default {
		pinctrl-single,pins = <
			J721E_WKUP_IOPAD(0x150, PIN_INPUT, 0) /* (N23) MCU_ADC1_AIN0 */
		>;
	};

	mikro_bus_pins_default: mikro-bus-pins-default {
		pinctrl-single,pins = <
			J721E_WKUP_IOPAD(0x108, PIN_INPUT, 7) /* SDAPULLEN (E26) PMIC_POWER_EN0.WKUP_GPIO0_66 */
			J721E_WKUP_IOPAD(0xd4, PIN_INPUT, 7) /* SDA (G26) WKUP_GPIO0_9.MCU_I2C1_SDA */
			J721E_WKUP_IOPAD(0xf4, PIN_INPUT, 7) /* SDA (D25) MCU_I3C0_SDA.WKUP_GPIO0_61 */
			J721E_WKUP_IOPAD(0xd0, PIN_INPUT, 7) /* SCL (G27) WKUP_GPIO0_8.MCU_I2C1_SCL */
			J721E_WKUP_IOPAD(0xf0, PIN_INPUT, 7) /* SCL (D26) MCU_I3C0_SCL.WKUP_GPIO0_60 */

			J721E_WKUP_IOPAD(0xb8, PIN_INPUT, 7) /* MOSI (F28) WKUP_GPIO0_2.MCU_SPI1_D1 */
			J721E_WKUP_IOPAD(0xb4, PIN_INPUT, 7) /* MISO (F25) WKUP_GPIO0_1.MCU_SPI1_D0 */
			J721E_WKUP_IOPAD(0xb0, PIN_INPUT, 7) /* CLK (F26) WKUP_GPIO0_0.MCU_SPI1_CLK */
			J721E_WKUP_IOPAD(0xbc, PIN_INPUT, 7) /* CS (F27) WKUP_GPIO0_3.MCU_SPI1_CS0 */

			J721E_WKUP_IOPAD(0x44, PIN_INPUT, 7) /* RX (G22) MCU_OSPI1_D1.WKUP_GPIO0_33 */
			J721E_WKUP_IOPAD(0x48, PIN_INPUT, 7) /* TX (D23) MCU_OSPI1_D2.WKUP_GPIO0_34 */

			J721E_WKUP_IOPAD(0x4c, PIN_INPUT, 7) /* INT (C23) MCU_OSPI1_D3.WKUP_GPIO0_35 */
			J721E_WKUP_IOPAD(0x54, PIN_INPUT, 7) /* RST (E22) MCU_OSPI1_CSn1.WKUP_GPIO0_37 */
			J721E_WKUP_IOPAD(0xdc, PIN_INPUT, 7) /* PWM (H27) WKUP_GPIO0_11 */
			J721E_WKUP_IOPAD(0xac, PIN_INPUT, 7) /* AN (C29) MCU_MCAN0_RX.WKUP_GPIO0_59 */
		>;
	};

	sw_pwr_pins_default: sw-pwr-pins-default {
		pinctrl-single,pins = <
			J721E_WKUP_IOPAD(0xc0, PIN_INPUT, 7) /* (G25) WKUP_GPIO0_4 */
		>;
	};

	mcu_cpsw_pins_default: mcu-cpsw-pins-default {
		pinctrl-single,pins = <
			J721E_WKUP_IOPAD(0x84, PIN_INPUT, 0) /* (B24) MCU_RGMII1_RD0 */
			J721E_WKUP_IOPAD(0x80, PIN_INPUT, 0) /* (A24) MCU_RGMII1_RD1 */
			J721E_WKUP_IOPAD(0x7c, PIN_INPUT, 0) /* (D24) MCU_RGMII1_RD2 */
			J721E_WKUP_IOPAD(0x78, PIN_INPUT, 0) /* (A25) MCU_RGMII1_RD3 */
			J721E_WKUP_IOPAD(0x74, PIN_INPUT, 0) /* (C24) MCU_RGMII1_RXC */
			J721E_WKUP_IOPAD(0x5c, PIN_INPUT, 0) /* (C25) MCU_RGMII1_RX_CTL */
			J721E_WKUP_IOPAD(0x6c, PIN_OUTPUT, 0) /* (B25) MCU_RGMII1_TD0 */
			J721E_WKUP_IOPAD(0x68, PIN_OUTPUT, 0) /* (A26) MCU_RGMII1_TD1 */
			J721E_WKUP_IOPAD(0x64, PIN_OUTPUT, 0) /* (A27) MCU_RGMII1_TD2 */
			J721E_WKUP_IOPAD(0x60, PIN_OUTPUT, 0) /* (A28) MCU_RGMII1_TD3 */
			J721E_WKUP_IOPAD(0x70, PIN_OUTPUT, 0) /* (B26) MCU_RGMII1_TXC */
			J721E_WKUP_IOPAD(0x58, PIN_OUTPUT, 0) /* (B27) MCU_RGMII1_TX_CTL */
		>;
	};

	mcu_mdio_pins_default: mcu-mdio1-pins-default {
		pinctrl-single,pins = <
			J721E_WKUP_IOPAD(0x8c, PIN_OUTPUT, 0) /* (F23) MCU_MDIO0_MDC */
			J721E_WKUP_IOPAD(0x88, PIN_INPUT, 0) /* (E23) MCU_MDIO0_MDIO */
		>;
	};

	mcu_usbss1_pins_default: mcu-usbss1-pins-default {
		pinctrl-single,pins = <
			J721E_WKUP_IOPAD(0x3c, PIN_OUTPUT_PULLUP, 5) /* (A23) MCU_OSPI1_LBCLKO.WKUP_GPIO0_30 */
		>;
	};
};

&wkup_uart0 {
	/* Wakeup UART is used by System firmware */
	status = "reserved";
};

bone_uart_0: &main_uart0 {
	/* TODO: also has option as "bone/uart/4" */
	symlink = "bone/uart/0";
	power-domains = <&k3_pds 146 TI_SCI_PD_SHARED>;
};

&main_uart3 {
	/* UART not brought out */
	status = "disabled";
};

bone_uart_5: &main_uart5 {
	symlink = "bone/uart/5";
	status = "disabled";
};

&main_uart6 {
	/* UART not brought out */
	status = "disabled";
};

&main_uart7 {
	/* UART not brought out */
	status = "disabled";
};

&main_uart8 {
	/* UART not brought out */
	status = "disabled";
};

&main_uart9 {
	/* UART not brought out */
	status = "disabled";
};

&main_gpio0 {
	status = "okay";
	gpio-line-names = "", "P9_11", "P9_13", "P8_17", "P8_18", /* 0-4 */
		"P8_22", "P8_24", "P8_34", "P8_36", "P8_38A", /* 5-9 */
		"P9_23", "P8_37B", "P9_26B", "P9_24B", "P8_08", /* 10-14 */
		"P8_07", "P8_10", "P8_09", "P9_42B", "", /* 15-19 */
		"P8_03", "TYPEC_PWR_ST", "M2_RSTz", "M2_I2C_ALERT#", "P8_35A", /* 20-24 */
		"P8_33A", "P8_32A", "", "P9_17A", "", /* 25-29 */
		"P8_21", "P8_23", "P8_31A", "P8_05", "P8_06", /* 30-34 */
		"P8_25", "M2_W_DISABLE1#", "M2_W_DISABLE2#", "P9_22A (BOOTMODE1)", "P9_21A", /* 35-39 */
		"P9_18A", "DSI_I2C_SCL", "DSI_I2C_SDA", "P9_28B", "P9_30B", /* 40-44 */
		"P9_12", "P9_27A", "P9_15", "P8_04 (BOOTMODE2)", "VCC_DP_EN", /* 45-49 */
		"P9_33B", "P8_26", "P9_31B", "P9_29B", "P9_39B", /* 50-54 */
		"P9_35B", "P9_36B", "P9_37B", "P9_38B", "P8_12", /* 55-59 */
		"P8_11 (BOOTMODE7)", "P8_15", "P8_16", "", "", /* 60-64 */
		"P8_43", "P8_44", "P8_41", "P8_42 (BOOTMODE6)", "P8_39", /* 65-69 */
		"P8_40", "P8_27", "P8_28", "P8_29", "P8_30", /* 70-74 */
		"P8_14", "P8_20", "P9_20B", "P9_19B", "P8_45", /* 75-79 */
		"P8_46 (BOOTMODE3)", "P9_40B", "VDD_SD_EN", "CSI_I2C_SCL", "CSI_I2C_SDA", /* 80-84 */
		"M2_I2S_SCK", "M2_I2S_WS", "M2_I2S_IN", "P8_19", "P8_13", /* 85-89 */
		"P9_21B", "P9_22B", "M2_I2S_OUT", "P9_14", "P9_16", /* 90-94 */
		"USR1", "USR0", "USR2", "DSI_GPIO1", "FAN_PWM", /* 95-99 */
		"FAN_TACH", "CSI1_GPIO1", "CSI0_GPIO2", "CSI0_GPIO1", "P9_25B", /* 100-104 */
		"P8_38B", "P8_37A", "CSI1_GPIO2", "DSI_GPIO2", "USR4", /* 105-109 */
		"USR3", "P8_33B", "DP_HPD", "M2_UART_CTSn", "M2_UART_RTSn", /* 110-114 */
		"P9_17B", "P8_35B", "VDD_SD_SEL", "P9_26A", "P9_24A", /* 115-119 */
		"P9_18B", "CONSOLE_RX", "CONSOLE_TX", "P9_42A", "P9_27B", /* 120-124 */
		"M2_UART_RX", "M2_UART_TX", "P9_25A"; /* 125-127 */
};

&main_gpio1 {
	status = "okay";
	gpio-line-names = "P9_41", "P9_19A", "P9_20A", "TYPEC_DIR", "TYPEC_INT", /* 0-4 */
		"M2_PCIE_WAKE#", "M2_PCIE_CLKREQ#", "M2_I2C_SCL", "M2_I2C_SDA", "TYPEC/CSI1_I2C_SCL", /* 5-9 */
		"TYPEC/CSI1_I2C_SDA", "P9_28A", "P9_31A", "P9_30A", "P9_29A", /* 10-14 */
		"uSD_DAT3", "uSD_DAT2", "uSD_DAT1", "uSD_DAT0", "uSD_CLK", /* 15-19 */
		"uSD_CMD", "uSD_SDCD", "", "M2_SDIO_DAT3", "M2_SDIO_DAT2", /* 20-24 */
		"M2_SDIO_DAT1", "M2_SDIO_DAT0", "M2_SDIO_CLK", "M2_SDIO_CMD", "USB1_DRVVBUS", /* 25-29 */
		"", "", "", "", "", /* 30-34 */
		"", ""; /* 35-36 */
};

&main_gpio2 {
	status = "disabled";
};

&main_gpio3 {
	status = "disabled";
};

&main_gpio4 {
	status = "disabled";
};

&main_gpio5 {
	status = "disabled";
};

&main_gpio6 {
	status = "disabled";
};

&main_gpio7 {
	status = "disabled";
};

&wkup_gpio0 {
	pinctrl-names = "default";
	pinctrl-0 = <&mcu_adc0_pins_default &mcu_adc1_pins_default &mikro_bus_pins_default>;
	gpio-line-names = "MB_CLK/BOOT_BTN", "MB_MISO", "MB_MOSI", "MB_CS", "SOC_WAKE", /* 0-4 */
		"EEPROM_WP", "SOC_INT2z", "H_MCU_INT#", "MB_SCLA", "MB_SDAA", /* 5-9 */
		"MCU_RGMII_RST#", "MB_PWM", "MCU_BOOTMODE8", "MCU_BOOTMODE9", "MCU_BOOTMODE6", /* 10-14 */
		"MCU_BOOTMODE7", "", "", "", "", /* 15-19 */
		"", "", "", "", "", /* 20-24 */
		"", "", "", "", "", /* 24-29 */
		"USB_HUB_RST", "", "", "MB_RX", "MB_TX", /* 30-34 */
		"MB_INT", "", "MB_RST", "MII_TX_CTL", "MII_RX_CTL", /* 35-39 */
		"MII_TD3", "MII_TD2", "MII_TD1", "MII_TD0", "MII_TXC", /* 40-44 */
		"MII_RXC", "MII_RD3", "MII_RD2", "MII_RD1", "MII_RD0", /* 45-49 */
		"MDIO", "MDC", "MCU_BOOTMODE0", "MCU_BOOTMODE1", "MCU_BOOTMODE2", /* 50-54 */
		"SYS_MCU_PWRDN", "WKUP_UART_RX", "WKUP_UART_TX", "MII_RST#", "MB_AN", /* 55-59 */
		"MB_SCLB", "MB_SDAB", "WKUP_I2C0_SCL", "WKUP_I2C0_SDA", "MCU_I2C0_SCL", /* 60-64 */
		"MCU_I2C0_SDA", "MB_SDAPULLEN", "PMIC_POWER_EN1"; /* 65-67 */
};

&wkup_gpio1 {
	status = "disabled";
};

&main_sdhci0 {
	/* eMMC */
	non-removable;
	ti,driver-strength-ohm = <50>;
	disable-wp;
};

&main_sdhci1 {
	/* SD/MMC */
	vmmc-supply = <&vdd_mmc1>;
	vqmmc-supply = <&vdd_sd_dv_alt>;
	pinctrl-names = "default";
	pinctrl-0 = <&main_mmc1_pins_default>;
	ti,driver-strength-ohm = <50>;
	disable-wp;
};

&main_sdhci2 {
	/* Unused */
	status = "disabled";
};

&usb_serdes_mux {
	idle-states = <1>, <1>; /* USB0 to SERDES3, USB1 to SERDES2 */
};

&serdes_ln_ctrl {
	idle-states = <J721E_SERDES0_LANE0_IP4_UNUSED>, <J721E_SERDES0_LANE1_IP4_UNUSED>, /* TODO: is this right? */
		      <J721E_SERDES1_LANE0_PCIE1_LANE0>, <J721E_SERDES1_LANE1_PCIE1_LANE1>,
		      <J721E_SERDES2_LANE0_IP1_UNUSED>, <J721E_SERDES2_LANE1_USB3_1>, /* TODO: USB3_0 or USB3_1? */
		      <J721E_SERDES3_LANE0_USB3_0_SWAP>, <J721E_SERDES3_LANE1_USB3_0>,
		      <J721E_SERDES4_LANE0_EDP_LANE0>, <J721E_SERDES4_LANE1_EDP_LANE1>,
		      <J721E_SERDES4_LANE2_EDP_LANE2>, <J721E_SERDES4_LANE3_EDP_LANE3>;
};

&serdes_wiz3 {
	typec-dir-gpios = <&main_gpio1 3 GPIO_ACTIVE_LOW>;
	typec-dir-debounce-ms = <700>;	/* TUSB321, tCCB_DEFAULT 133 ms */
};

&serdes3 {
	serdes3_usb_link: phy@0 {
		reg = <0>;
		cdns,num-lanes = <2>;
		#phy-cells = <0>;
		cdns,phy-type = <PHY_TYPE_USB3>;
		resets = <&serdes_wiz3 1>, <&serdes_wiz3 2>;
	};
};

&usbss0 {
	pinctrl-names = "default";
	pinctrl-0 = <&main_usbss0_pins_default>;
	ti,vbus-divider;
};

&usb0 {
	dr_mode = "peripheral";
	maximum-speed = "super-speed";
	phys = <&serdes3_usb_link>;
	phy-names = "cdns3,usb3-phy";
};

&serdes2 {
	serdes2_usb_link: phy@1 {
		reg = <1>;
		cdns,num-lanes = <1>;
		#phy-cells = <0>;
		cdns,phy-type = <PHY_TYPE_USB3>;
		resets = <&serdes_wiz2 2>;
	};
};

&usbss1 {
	pinctrl-names = "default";
	pinctrl-0 = <&main_usbss1_pins_default &mcu_usbss1_pins_default>;
	ti,vbus-divider;
};

&usb1 {
	dr_mode = "host";
	maximum-speed = "super-speed";
	phys = <&serdes2_usb_link>;
	phy-names = "cdns3,usb3-phy";
};

&tscadc0 {
	adc {
		ti,adc-channels = <0 1 2 3 4 5 6 7>;
	};
};

&tscadc1 {
	adc {
		ti,adc-channels = <0 1 2 3 4 5 6 7>;
	};
};

bone_i2c_0: &wkup_i2c0 {
	pinctrl-names = "default";
	pinctrl-0 = <&wkup_i2c0_pins_default &eeprom_wp_pins_default>;
	clock-frequency = <400000>;

	eeprom@50 {
		compatible = "atmel,24c04";
		reg = <0x50>;
	};
};

&main_i2c0 {
	pinctrl-names = "default";
	pinctrl-0 = <&main_i2c0_pins_default>;
	clock-frequency = <400000>;
};

&main_i2c1 {
	pinctrl-names = "default";
	pinctrl-0 = <&main_i2c1_pins_default &csi1_gpio_pins_default>;
	clock-frequency = <400000>;

#if 1
	ov5640_1: camera1@3c {
		compatible = "ovti,ov5640";
		reg = <0x3c>;

		clocks = <&clk_ov5640_fixed>;
		clock-names = "xclk";
		powerdown-gpios = <&main_gpio0 101 GPIO_ACTIVE_LOW>;
		reset-gpios = <&main_gpio0 107 GPIO_ACTIVE_LOW>;

		port {
			csi2rx1_cam0: endpoint {
				remote-endpoint = <&csi2rx1_in_sensor>;
				clock-lanes = <0>;
				data-lanes = <1 2>;
			};
		};
	};
#else
	ov5647_1: camera1@36 {
		compatible = "ovti,ov5647";
		reg = <0x36>;

		clocks = <&clk_ov5640_fixed>;
		clock-names = "xclk";
		powerdown-gpios = <&main_gpio0 101 GPIO_ACTIVE_LOW>;
		reset-gpios = <&main_gpio0 107 GPIO_ACTIVE_LOW>;

		port {
			csi2rx1_cam0: endpoint {
				remote-endpoint = <&csi2rx1_in_sensor>;
				clock-lanes = <0>;
				data-lanes = <1 2>;
			};
		};
	};
#endif

	tusb322@47 {
		compatible = "ti,tusb322";
		reg = <0x47>;
		pinctrl-names = "default";
		pinctrl-0 = <&tusb322_pins_default>;
		interrupt-parent = <&main_gpio1>;
		interrupts = <4 IRQ_TYPE_EDGE_FALLING>;
		interrupt-controller;
		#interrupt-cells = <2>;
	};
};

&main_i2c3 {
	pinctrl-names = "default";
	pinctrl-0 = <&main_i2c3_pins_default>;
	clock-frequency = <400000>;
};

&main_i2c5 {
	pinctrl-names = "default";
	pinctrl-0 = <&main_i2c5_pins_default &csi0_gpio_pins_default>;
	clock-frequency = <400000>;

#if 1
	ov5640: camera@3c {
		compatible = "ovti,ov5640";
		reg = <0x3c>;

		clocks = <&clk_ov5640_fixed>;
		clock-names = "xclk";
		powerdown-gpios = <&main_gpio0 103 GPIO_ACTIVE_LOW>;
		reset-gpios = <&main_gpio0 102 GPIO_ACTIVE_LOW>;

		port {
			csi2rx0_cam0: endpoint {
				remote-endpoint = <&csi2rx0_in_sensor>;
				clock-lanes = <0>;
				data-lanes = <1 2>;
			};
		};
	};
#else
	ov5647: camera1@36 {
		compatible = "ovti,ov5647";
		reg = <0x36>;

		clocks = <&clk_ov5640_fixed>;
		clock-names = "xclk";
		powerdown-gpios = <&main_gpio0 101 GPIO_ACTIVE_LOW>;
		reset-gpios = <&main_gpio0 107 GPIO_ACTIVE_LOW>;

		port {
			csi2rx0_cam0: endpoint {
				remote-endpoint = <&csi2rx0_in_sensor>;
				clock-lanes = <0>;
				data-lanes = <1 2>;
			};
		};
	};
#endif
};

//bone_spi_0: &main_spi6 {
//	pinctrl-names = "default";
//	pinctrl-0 = <&main_spi6_pins_default>;
//	ti,spi-num-cs = <2>;
//	ti,pindir-d0-out-d1-in;
//
//	spidev0: spidev@0{
//		symlink = "bone/spi/0.0";
//		compatible = "spidev";
//		reg = <0>;	/* CE0 */
//		#address-cells = <1>;
//		#size-cells = <0>;
//		spi-max-frequency = <125000000>;
//	};
//
//	spidev1: spidev@1{
//		symlink = "bone/spi/0.1";
//		compatible = "spidev";
//		reg = <1>;	/* CE1 */
//		#address-cells = <1>;
//		#size-cells = <0>;
//		spi-max-frequency = <125000000>;
//	};
//};

&mcu_cpsw {
	pinctrl-names = "default";
	pinctrl-0 = <&mcu_cpsw_pins_default &mcu_mdio_pins_default>;
};

&davinci_mdio {
	phy0: ethernet-phy@0 {
		reg = <0>;
		ti,rx-internal-delay = <DP83867_RGMIIDCTL_2_00_NS>;
		ti,fifo-depth = <DP83867_PHYCR_FIFO_DEPTH_4_B_NIB>;
	};
};

&cpsw_port1 {
	phy-mode = "rgmii-rxid";
	phy-handle = <&phy0>;
};

&dss {
	/*
	 * These clock assignments are chosen to enable the following outputs:
	 *
	 * VP0 - DisplayPort SST
	 * VP1 - DPI0
	 * VP2 - DSI
	 * VP3 - DPI1
	 */

	assigned-clocks = <&k3_clks 152 1>,
			  <&k3_clks 152 4>,
			  <&k3_clks 152 9>,
			  <&k3_clks 152 13>;
	assigned-clock-parents = <&k3_clks 152 2>,	/* PLL16_HSDIV0 */
				 <&k3_clks 152 6>,	/* PLL19_HSDIV0 */
				 <&k3_clks 152 11>,	/* PLL18_HSDIV0 */
				 <&k3_clks 152 18>;	/* PLL23_HSDIV0 */
};

&dss_ports {
	port@0 {
		reg = <0>;

		dpi0_out: endpoint {
			remote-endpoint = <&dp0_in>;
		};
	};
};

&mhdp {
	pinctrl-names = "default";
	pinctrl-0 = <&dp0_pins_default>;
};

&dp0_ports {
	#address-cells = <1>;
	#size-cells = <0>;

	port@0 {
		reg = <0>;
		dp0_in: endpoint {
			remote-endpoint = <&dpi0_out>;
		};
	};

	port@4 {
		reg = <4>;
		dp0_out: endpoint {
			remote-endpoint = <&dp_connector_in>;
		};
	};
};

&mcasp0 {
	status = "disabled";
};

&mcasp1 {
	status = "disabled";
};

&mcasp2 {
	status = "disabled";
};

&mcasp3 {
	status = "disabled";
};

&mcasp4 {
	status = "disabled";
};

&mcasp5 {
	status = "disabled";
};

&mcasp6 {
	status = "disabled";
};

&mcasp7 {
	status = "disabled";
};

&mcasp8 {
	status = "disabled";
};

&mcasp9 {
	status = "disabled";
};

&mcasp10 {
	status = "disabled";
};

&mcasp11 {
	status = "disabled";
};

&serdes0 {
	serdes0_pcie_link: phy@0 {
		reg = <0>;
		cdns,num-lanes = <1>;
		#phy-cells = <0>;
		cdns,phy-type = <PHY_TYPE_PCIE>;
		resets = <&serdes_wiz0 1>;
	};
};

&serdes1 {
	serdes1_pcie_link: phy@0 {
		reg = <0>;
		cdns,num-lanes = <2>;
		#phy-cells = <0>;
		cdns,phy-type = <PHY_TYPE_PCIE>;
		resets = <&serdes_wiz1 1>, <&serdes_wiz1 2>;
	};
};

&pcie0_rc {
	status = "disabled";
};

&pcie1_rc {
	pinctrl-names = "default";
	pinctrl-0 = <&pcie1_rst_pins_default>;
	phys = <&serdes1_pcie_link>;
	phy-names = "pcie-phy";
	num-lanes = <2>;
	max-link-speed = <3>;
	reset-gpios = <&main_gpio0 22 GPIO_ACTIVE_HIGH>;
};

&pcie2_rc {
	status = "disabled";
};

&pcie0_ep {
	phys = <&serdes0_pcie_link>;
	phy-names = "pcie-phy";
	num-lanes = <1>;
	status = "disabled";
};

&pcie1_ep {
	phys = <&serdes1_pcie_link>;
	phy-names = "pcie-phy";
	num-lanes = <2>;
	status = "disabled";
};

&pcie2_ep {
	status = "disabled";
};

&pcie3_rc {
	status = "disabled";
};

&pcie3_ep {
	status = "disabled";
};

/* TODO: is uart2 assigned to cpsw9g eth-switch fw running on remote CPU core? */
/* TODO: handle alternate connection at P8_34 and P8_22 */
bone_uart_1: &main_uart2 {
	status = "okay";
	symlink = "bone/uart/1";
	power-domains = <&k3_pds 279 TI_SCI_PD_SHARED>; /* TODO: needed? */
};

&mcu_mcan0 {
	status = "disabled";
};

&mcu_mcan1 {
	status = "disabled";
};

&main_mcan0 {
	status = "disabled";
};

&main_mcan1 {
	status = "disabled";
};

&main_mcan2 {
	status = "disabled";
};

&main_mcan3 {
	status = "disabled";
};

&main_mcan4 {
	status = "disabled";
};

&main_mcan5 {
	status = "disabled";
};

&main_mcan6 {
	status = "disabled";
};

&main_mcan7 {
	status = "disabled";
};

&main_mcan8 {
	status = "disabled";
};

&main_mcan9 {
	status = "disabled";
};

&main_mcan10 {
	status = "disabled";
};

&main_mcan11 {
	status = "disabled";
};

&main_mcan12 {
	status = "disabled";
};

&main_mcan13 {
	status = "disabled";
};

&ufs_wrapper {
	status = "disabled";
};

&csi0_port0 {
	csi2rx0_in_sensor: endpoint {
		remote-endpoint = <&csi2rx0_cam0>;
		bus-type = <4>; /* CSI2 DPHY. */
		clock-lanes = <0>;
		data-lanes = <1 2>;
	};
};

&csi0_port1 {
	status = "disabled";
};

&csi0_port2 {
	status = "disabled";
};

&csi0_port3 {
	status = "disabled";
};

&csi0_port4 {
	status = "disabled";
};

&csi1_port0 {
	csi2rx1_in_sensor: endpoint {
		remote-endpoint = <&csi2rx1_cam0>;
		bus-type = <4>; /* CSI2 DPHY. */
		clock-lanes = <0>;
		data-lanes = <1 2>;
	};
};

&csi1_port1 {
	status = "disabled";
};

&csi1_port2 {
	status = "disabled";
};

&csi1_port3 {
	status = "disabled";
};

&csi1_port4 {
	status = "disabled";
};
